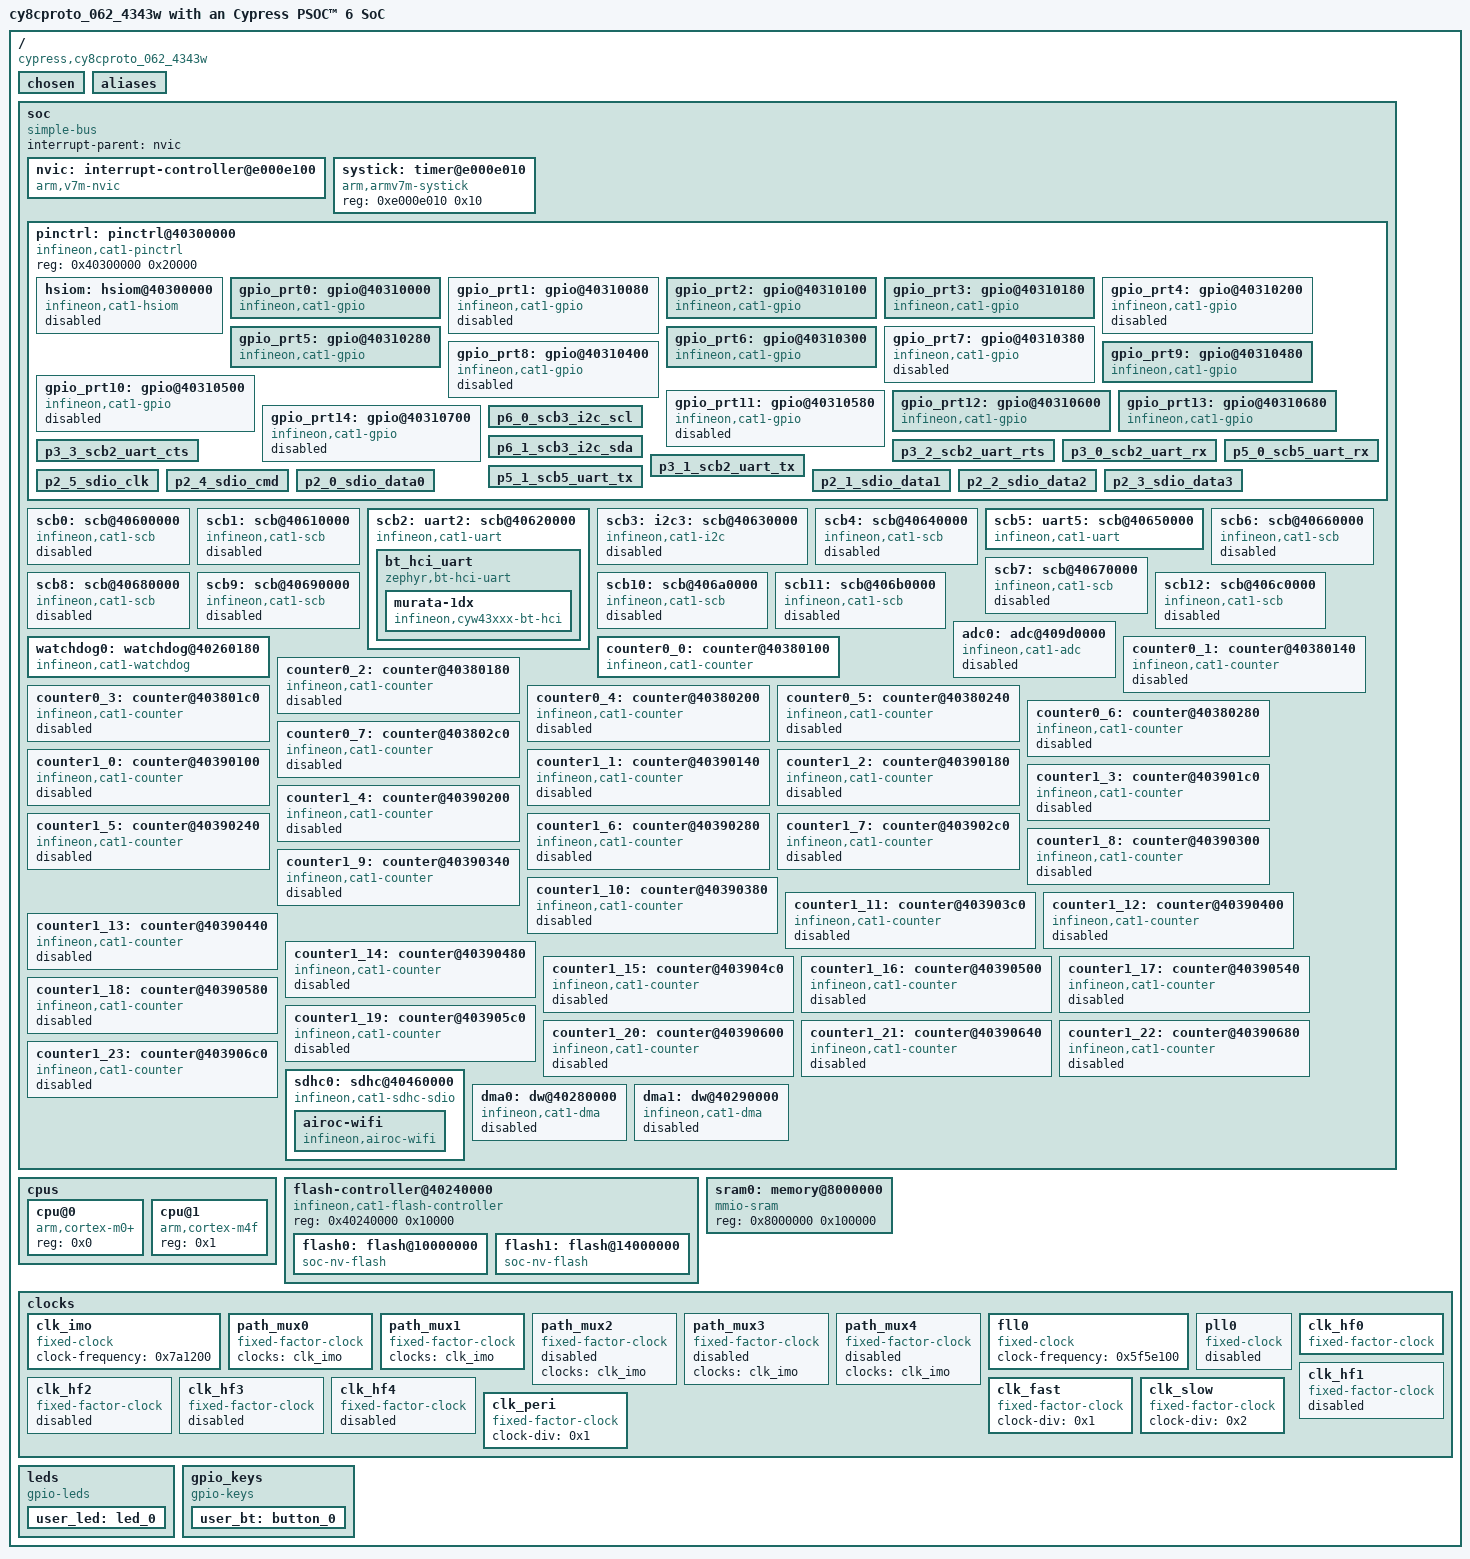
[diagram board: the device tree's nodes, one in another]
/dts-v1/;

/* node '/' defined in zephyr/dts/common/skeleton.dtsi:9 */
/ {
	#address-cells = < 0x1 >;                                  /* in zephyr/dts/common/skeleton.dtsi:10 */
	#size-cells = < 0x1 >;                                     /* in zephyr/dts/common/skeleton.dtsi:11 */
	model = "cy8cproto_062_4343w with an Cypress PSOC™ 6 SoC"; /* in zephyr/boards/infineon/cy8cproto_062_4343w/cy8cproto_062_4343w.dts:13 */
	compatible = "cypress,cy8cproto_062_4343w",
	             "cypress,PSOC6";                              /* in zephyr/boards/infineon/cy8cproto_062_4343w/cy8cproto_062_4343w.dts:14 */

	/* node '/chosen' defined in zephyr/dts/common/skeleton.dtsi:13 */
	chosen {
		zephyr,sram = &sram0;         /* in zephyr/boards/infineon/cy8cproto_062_4343w/cy8cproto_062_4343w.dts:24 */
		zephyr,flash = &flash0;       /* in zephyr/boards/infineon/cy8cproto_062_4343w/cy8cproto_062_4343w.dts:25 */
		zephyr,console = &uart5;      /* in zephyr/boards/infineon/cy8cproto_062_4343w/cy8cproto_062_4343w.dts:26 */
		zephyr,shell-uart = &uart5;   /* in zephyr/boards/infineon/cy8cproto_062_4343w/cy8cproto_062_4343w.dts:27 */
		zephyr,bt-hci = &bt_hci_uart; /* in zephyr/boards/infineon/cy8cproto_062_4343w/cy8cproto_062_4343w.dts:28 */
	};

	/* node '/aliases' defined in zephyr/dts/common/skeleton.dtsi:15 */
	aliases {
		led0 = &user_led;       /* in zephyr/boards/infineon/cy8cproto_062_4343w/cy8cproto_062_4343w-common.dtsi:10 */
		sw0 = &user_bt;         /* in zephyr/boards/infineon/cy8cproto_062_4343w/cy8cproto_062_4343w-common.dtsi:11 */
		uart-5 = &uart5;        /* in zephyr/boards/infineon/cy8cproto_062_4343w/cy8cproto_062_4343w.dts:17 */
		i2c-0 = &i2c3;          /* in zephyr/boards/infineon/cy8cproto_062_4343w/cy8cproto_062_4343w.dts:18 */
		watchdog0 = &watchdog0; /* in zephyr/boards/infineon/cy8cproto_062_4343w/cy8cproto_062_4343w.dts:19 */
		sdhc0 = &sdhc0;         /* in zephyr/boards/infineon/cy8cproto_062_4343w/cy8cproto_062_4343w.dts:20 */
	};

	/* node '/soc' defined in zephyr/dts/arm/armv7-m.dtsi:6 */
	soc {
		#address-cells = < 0x1 >;     /* in zephyr/dts/arm/armv7-m.dtsi:7 */
		#size-cells = < 0x1 >;        /* in zephyr/dts/arm/armv7-m.dtsi:8 */
		compatible = "simple-bus";    /* in zephyr/dts/arm/armv7-m.dtsi:9 */
		interrupt-parent = < &nvic >; /* in zephyr/dts/arm/armv7-m.dtsi:10 */
		ranges;                       /* in zephyr/dts/arm/armv7-m.dtsi:11 */

		/* node '/soc/interrupt-controller@e000e100' defined in zephyr/dts/arm/armv7-m.dtsi:13 */
		nvic: interrupt-controller@e000e100 {
			#address-cells = < 0x1 >;            /* in zephyr/dts/arm/armv7-m.dtsi:14 */
			compatible = "arm,v7m-nvic";         /* in zephyr/dts/arm/armv7-m.dtsi:15 */
			reg = < 0xe000e100 0xc00 >;          /* in zephyr/dts/arm/armv7-m.dtsi:16 */
			interrupt-controller;                /* in zephyr/dts/arm/armv7-m.dtsi:17 */
			#interrupt-cells = < 0x2 >;          /* in zephyr/dts/arm/armv7-m.dtsi:18 */
			arm,num-irq-priority-bits = < 0x3 >; /* in zephyr/dts/arm/infineon/cat1a/mpns/CY8C624ABZI_S2D44.dtsi:12 */
			phandle = < 0x1 >;                   /* in zephyr/dts/arm/armv7-m.dtsi:10 */
		};

		/* node '/soc/timer@e000e010' defined in zephyr/dts/arm/armv7-m.dtsi:21 */
		systick: timer@e000e010 {
			compatible = "arm,armv7m-systick"; /* in zephyr/dts/arm/armv7-m.dtsi:22 */
			reg = < 0xe000e010 0x10 >;         /* in zephyr/dts/arm/armv7-m.dtsi:23 */
		};

		/* node '/soc/pinctrl@40300000' defined in zephyr/dts/arm/infineon/cat1a/psoc6_02/psoc6_02.dtsi:55 */
		pinctrl: pinctrl@40300000 {
			compatible = "infineon,cat1-pinctrl"; /* in zephyr/dts/arm/infineon/cat1a/psoc6_02/psoc6_02.dtsi:56 */
			reg = < 0x40300000 0x20000 >;         /* in zephyr/dts/arm/infineon/cat1a/psoc6_02/psoc6_02.dtsi:57 */
			#address-cells = < 0x1 >;             /* in zephyr/dts/arm/infineon/cat1a/psoc6_02/psoc6_02.dtsi:58 */
			#size-cells = < 0x0 >;                /* in zephyr/dts/arm/infineon/cat1a/psoc6_02/psoc6_02.dtsi:59 */

			/* node '/soc/pinctrl@40300000/hsiom@40300000' defined in zephyr/dts/arm/infineon/cat1a/psoc6_02/psoc6_02.dtsi:61 */
			hsiom: hsiom@40300000 {
				compatible = "infineon,cat1-hsiom"; /* in zephyr/dts/arm/infineon/cat1a/psoc6_02/psoc6_02.dtsi:62 */
				reg = < 0x40300000 0x4000 >;        /* in zephyr/dts/arm/infineon/cat1a/psoc6_02/psoc6_02.dtsi:63 */
				interrupts = < 0xf 0x6 >,
				             < 0x10 0x6 >;          /* in zephyr/dts/arm/infineon/cat1a/psoc6_02/psoc6_02.dtsi:64 */
				status = "disabled";                /* in zephyr/dts/arm/infineon/cat1a/psoc6_02/psoc6_02.dtsi:65 */
			};

			/* node '/soc/pinctrl@40300000/gpio@40310000' defined in zephyr/dts/arm/infineon/cat1a/psoc6_02/psoc6_02.dtsi:68 */
			gpio_prt0: gpio@40310000 {
				compatible = "infineon,cat1-gpio"; /* in zephyr/dts/arm/infineon/cat1a/psoc6_02/psoc6_02.dtsi:69 */
				reg = < 0x40310000 0x80 >;         /* in zephyr/dts/arm/infineon/cat1a/psoc6_02/psoc6_02.dtsi:70 */
				interrupts = < 0x0 0x6 >;          /* in zephyr/dts/arm/infineon/cat1a/psoc6_02/psoc6_02.dtsi:71 */
				gpio-controller;                   /* in zephyr/dts/arm/infineon/cat1a/psoc6_02/psoc6_02.dtsi:72 */
				ngpios = < 0x6 >;                  /* in zephyr/dts/arm/infineon/cat1a/psoc6_02/psoc6_02.dtsi:73 */
				#gpio-cells = < 0x2 >;             /* in zephyr/dts/arm/infineon/cat1a/psoc6_02/psoc6_02.dtsi:75 */
				status = "okay";                   /* in zephyr/boards/infineon/cy8cproto_062_4343w/cy8cproto_062_4343w-common.dtsi:35 */
				phandle = < 0x12 >;                /* in zephyr/boards/infineon/cy8cproto_062_4343w/cy8cproto_062_4343w.dts:95 */
			};

			/* node '/soc/pinctrl@40300000/gpio@40310080' defined in zephyr/dts/arm/infineon/cat1a/psoc6_02/psoc6_02.dtsi:78 */
			gpio_prt1: gpio@40310080 {
				compatible = "infineon,cat1-gpio"; /* in zephyr/dts/arm/infineon/cat1a/psoc6_02/psoc6_02.dtsi:79 */
				reg = < 0x40310080 0x80 >;         /* in zephyr/dts/arm/infineon/cat1a/psoc6_02/psoc6_02.dtsi:80 */
				interrupts = < 0x1 0x6 >;          /* in zephyr/dts/arm/infineon/cat1a/psoc6_02/psoc6_02.dtsi:81 */
				gpio-controller;                   /* in zephyr/dts/arm/infineon/cat1a/psoc6_02/psoc6_02.dtsi:82 */
				ngpios = < 0x6 >;                  /* in zephyr/dts/arm/infineon/cat1a/psoc6_02/psoc6_02.dtsi:83 */
				status = "disabled";               /* in zephyr/dts/arm/infineon/cat1a/psoc6_02/psoc6_02.dtsi:84 */
				#gpio-cells = < 0x2 >;             /* in zephyr/dts/arm/infineon/cat1a/psoc6_02/psoc6_02.dtsi:85 */
			};

			/* node '/soc/pinctrl@40300000/gpio@40310100' defined in zephyr/dts/arm/infineon/cat1a/psoc6_02/psoc6_02.dtsi:88 */
			gpio_prt2: gpio@40310100 {
				compatible = "infineon,cat1-gpio"; /* in zephyr/dts/arm/infineon/cat1a/psoc6_02/psoc6_02.dtsi:89 */
				reg = < 0x40310100 0x80 >;         /* in zephyr/dts/arm/infineon/cat1a/psoc6_02/psoc6_02.dtsi:90 */
				interrupts = < 0x2 0x6 >;          /* in zephyr/dts/arm/infineon/cat1a/psoc6_02/psoc6_02.dtsi:91 */
				gpio-controller;                   /* in zephyr/dts/arm/infineon/cat1a/psoc6_02/psoc6_02.dtsi:92 */
				ngpios = < 0x8 >;                  /* in zephyr/dts/arm/infineon/cat1a/psoc6_02/psoc6_02.dtsi:93 */
				#gpio-cells = < 0x2 >;             /* in zephyr/dts/arm/infineon/cat1a/psoc6_02/psoc6_02.dtsi:95 */
				status = "okay";                   /* in zephyr/boards/infineon/cy8cproto_062_4343w/cy8cproto_062_4343w-common.dtsi:39 */
				phandle = < 0x11 >;                /* in zephyr/boards/infineon/cy8cproto_062_4343w/cy8cproto_062_4343w.dts:94 */
			};

			/* node '/soc/pinctrl@40300000/gpio@40310180' defined in zephyr/dts/arm/infineon/cat1a/psoc6_02/psoc6_02.dtsi:98 */
			gpio_prt3: gpio@40310180 {
				compatible = "infineon,cat1-gpio"; /* in zephyr/dts/arm/infineon/cat1a/psoc6_02/psoc6_02.dtsi:99 */
				reg = < 0x40310180 0x80 >;         /* in zephyr/dts/arm/infineon/cat1a/psoc6_02/psoc6_02.dtsi:100 */
				interrupts = < 0x3 0x6 >;          /* in zephyr/dts/arm/infineon/cat1a/psoc6_02/psoc6_02.dtsi:101 */
				gpio-controller;                   /* in zephyr/dts/arm/infineon/cat1a/psoc6_02/psoc6_02.dtsi:102 */
				ngpios = < 0x6 >;                  /* in zephyr/dts/arm/infineon/cat1a/psoc6_02/psoc6_02.dtsi:103 */
				#gpio-cells = < 0x2 >;             /* in zephyr/dts/arm/infineon/cat1a/psoc6_02/psoc6_02.dtsi:105 */
				status = "okay";                   /* in zephyr/boards/infineon/cy8cproto_062_4343w/cy8cproto_062_4343w-common.dtsi:43 */
				phandle = < 0x6 >;                 /* in zephyr/boards/infineon/cy8cproto_062_4343w/cy8cproto_062_4343w.dts:67 */
			};

			/* node '/soc/pinctrl@40300000/gpio@40310200' defined in zephyr/dts/arm/infineon/cat1a/psoc6_02/psoc6_02.dtsi:108 */
			gpio_prt4: gpio@40310200 {
				compatible = "infineon,cat1-gpio"; /* in zephyr/dts/arm/infineon/cat1a/psoc6_02/psoc6_02.dtsi:109 */
				reg = < 0x40310200 0x80 >;         /* in zephyr/dts/arm/infineon/cat1a/psoc6_02/psoc6_02.dtsi:110 */
				interrupts = < 0x4 0x6 >;          /* in zephyr/dts/arm/infineon/cat1a/psoc6_02/psoc6_02.dtsi:111 */
				gpio-controller;                   /* in zephyr/dts/arm/infineon/cat1a/psoc6_02/psoc6_02.dtsi:112 */
				ngpios = < 0x2 >;                  /* in zephyr/dts/arm/infineon/cat1a/psoc6_02/psoc6_02.dtsi:113 */
				status = "disabled";               /* in zephyr/dts/arm/infineon/cat1a/psoc6_02/psoc6_02.dtsi:114 */
				#gpio-cells = < 0x2 >;             /* in zephyr/dts/arm/infineon/cat1a/psoc6_02/psoc6_02.dtsi:115 */
			};

			/* node '/soc/pinctrl@40300000/gpio@40310280' defined in zephyr/dts/arm/infineon/cat1a/psoc6_02/psoc6_02.dtsi:118 */
			gpio_prt5: gpio@40310280 {
				compatible = "infineon,cat1-gpio"; /* in zephyr/dts/arm/infineon/cat1a/psoc6_02/psoc6_02.dtsi:119 */
				reg = < 0x40310280 0x80 >;         /* in zephyr/dts/arm/infineon/cat1a/psoc6_02/psoc6_02.dtsi:120 */
				interrupts = < 0x5 0x6 >;          /* in zephyr/dts/arm/infineon/cat1a/psoc6_02/psoc6_02.dtsi:121 */
				gpio-controller;                   /* in zephyr/dts/arm/infineon/cat1a/psoc6_02/psoc6_02.dtsi:122 */
				ngpios = < 0x8 >;                  /* in zephyr/dts/arm/infineon/cat1a/psoc6_02/psoc6_02.dtsi:123 */
				#gpio-cells = < 0x2 >;             /* in zephyr/dts/arm/infineon/cat1a/psoc6_02/psoc6_02.dtsi:125 */
				status = "okay";                   /* in zephyr/boards/infineon/cy8cproto_062_4343w/cy8cproto_062_4343w-common.dtsi:47 */
			};

			/* node '/soc/pinctrl@40300000/gpio@40310300' defined in zephyr/dts/arm/infineon/cat1a/psoc6_02/psoc6_02.dtsi:128 */
			gpio_prt6: gpio@40310300 {
				compatible = "infineon,cat1-gpio"; /* in zephyr/dts/arm/infineon/cat1a/psoc6_02/psoc6_02.dtsi:129 */
				reg = < 0x40310300 0x80 >;         /* in zephyr/dts/arm/infineon/cat1a/psoc6_02/psoc6_02.dtsi:130 */
				interrupts = < 0x6 0x6 >;          /* in zephyr/dts/arm/infineon/cat1a/psoc6_02/psoc6_02.dtsi:131 */
				gpio-controller;                   /* in zephyr/dts/arm/infineon/cat1a/psoc6_02/psoc6_02.dtsi:132 */
				ngpios = < 0x8 >;                  /* in zephyr/dts/arm/infineon/cat1a/psoc6_02/psoc6_02.dtsi:133 */
				#gpio-cells = < 0x2 >;             /* in zephyr/dts/arm/infineon/cat1a/psoc6_02/psoc6_02.dtsi:135 */
				status = "okay";                   /* in zephyr/boards/infineon/cy8cproto_062_4343w/cy8cproto_062_4343w-common.dtsi:51 */
			};

			/* node '/soc/pinctrl@40300000/gpio@40310380' defined in zephyr/dts/arm/infineon/cat1a/psoc6_02/psoc6_02.dtsi:138 */
			gpio_prt7: gpio@40310380 {
				compatible = "infineon,cat1-gpio"; /* in zephyr/dts/arm/infineon/cat1a/psoc6_02/psoc6_02.dtsi:139 */
				reg = < 0x40310380 0x80 >;         /* in zephyr/dts/arm/infineon/cat1a/psoc6_02/psoc6_02.dtsi:140 */
				interrupts = < 0x7 0x6 >;          /* in zephyr/dts/arm/infineon/cat1a/psoc6_02/psoc6_02.dtsi:141 */
				gpio-controller;                   /* in zephyr/dts/arm/infineon/cat1a/psoc6_02/psoc6_02.dtsi:142 */
				ngpios = < 0x8 >;                  /* in zephyr/dts/arm/infineon/cat1a/psoc6_02/psoc6_02.dtsi:143 */
				status = "disabled";               /* in zephyr/dts/arm/infineon/cat1a/psoc6_02/psoc6_02.dtsi:144 */
				#gpio-cells = < 0x2 >;             /* in zephyr/dts/arm/infineon/cat1a/psoc6_02/psoc6_02.dtsi:145 */
			};

			/* node '/soc/pinctrl@40300000/gpio@40310400' defined in zephyr/dts/arm/infineon/cat1a/psoc6_02/psoc6_02.dtsi:148 */
			gpio_prt8: gpio@40310400 {
				compatible = "infineon,cat1-gpio"; /* in zephyr/dts/arm/infineon/cat1a/psoc6_02/psoc6_02.dtsi:149 */
				reg = < 0x40310400 0x80 >;         /* in zephyr/dts/arm/infineon/cat1a/psoc6_02/psoc6_02.dtsi:150 */
				interrupts = < 0x8 0x6 >;          /* in zephyr/dts/arm/infineon/cat1a/psoc6_02/psoc6_02.dtsi:151 */
				gpio-controller;                   /* in zephyr/dts/arm/infineon/cat1a/psoc6_02/psoc6_02.dtsi:152 */
				ngpios = < 0x8 >;                  /* in zephyr/dts/arm/infineon/cat1a/psoc6_02/psoc6_02.dtsi:153 */
				status = "disabled";               /* in zephyr/dts/arm/infineon/cat1a/psoc6_02/psoc6_02.dtsi:154 */
				#gpio-cells = < 0x2 >;             /* in zephyr/dts/arm/infineon/cat1a/psoc6_02/psoc6_02.dtsi:155 */
			};

			/* node '/soc/pinctrl@40300000/gpio@40310480' defined in zephyr/dts/arm/infineon/cat1a/psoc6_02/psoc6_02.dtsi:158 */
			gpio_prt9: gpio@40310480 {
				compatible = "infineon,cat1-gpio"; /* in zephyr/dts/arm/infineon/cat1a/psoc6_02/psoc6_02.dtsi:159 */
				reg = < 0x40310480 0x80 >;         /* in zephyr/dts/arm/infineon/cat1a/psoc6_02/psoc6_02.dtsi:160 */
				interrupts = < 0x9 0x6 >;          /* in zephyr/dts/arm/infineon/cat1a/psoc6_02/psoc6_02.dtsi:161 */
				gpio-controller;                   /* in zephyr/dts/arm/infineon/cat1a/psoc6_02/psoc6_02.dtsi:162 */
				ngpios = < 0x8 >;                  /* in zephyr/dts/arm/infineon/cat1a/psoc6_02/psoc6_02.dtsi:163 */
				#gpio-cells = < 0x2 >;             /* in zephyr/dts/arm/infineon/cat1a/psoc6_02/psoc6_02.dtsi:165 */
				status = "okay";                   /* in zephyr/boards/infineon/cy8cproto_062_4343w/cy8cproto_062_4343w-common.dtsi:55 */
			};

			/* node '/soc/pinctrl@40300000/gpio@40310500' defined in zephyr/dts/arm/infineon/cat1a/psoc6_02/psoc6_02.dtsi:168 */
			gpio_prt10: gpio@40310500 {
				compatible = "infineon,cat1-gpio"; /* in zephyr/dts/arm/infineon/cat1a/psoc6_02/psoc6_02.dtsi:169 */
				reg = < 0x40310500 0x80 >;         /* in zephyr/dts/arm/infineon/cat1a/psoc6_02/psoc6_02.dtsi:170 */
				interrupts = < 0xa 0x6 >;          /* in zephyr/dts/arm/infineon/cat1a/psoc6_02/psoc6_02.dtsi:171 */
				gpio-controller;                   /* in zephyr/dts/arm/infineon/cat1a/psoc6_02/psoc6_02.dtsi:172 */
				ngpios = < 0x8 >;                  /* in zephyr/dts/arm/infineon/cat1a/psoc6_02/psoc6_02.dtsi:173 */
				status = "disabled";               /* in zephyr/dts/arm/infineon/cat1a/psoc6_02/psoc6_02.dtsi:174 */
				#gpio-cells = < 0x2 >;             /* in zephyr/dts/arm/infineon/cat1a/psoc6_02/psoc6_02.dtsi:175 */
			};

			/* node '/soc/pinctrl@40300000/gpio@40310580' defined in zephyr/dts/arm/infineon/cat1a/psoc6_02/psoc6_02.dtsi:178 */
			gpio_prt11: gpio@40310580 {
				compatible = "infineon,cat1-gpio"; /* in zephyr/dts/arm/infineon/cat1a/psoc6_02/psoc6_02.dtsi:179 */
				reg = < 0x40310580 0x80 >;         /* in zephyr/dts/arm/infineon/cat1a/psoc6_02/psoc6_02.dtsi:180 */
				interrupts = < 0xb 0x6 >;          /* in zephyr/dts/arm/infineon/cat1a/psoc6_02/psoc6_02.dtsi:181 */
				gpio-controller;                   /* in zephyr/dts/arm/infineon/cat1a/psoc6_02/psoc6_02.dtsi:182 */
				ngpios = < 0x8 >;                  /* in zephyr/dts/arm/infineon/cat1a/psoc6_02/psoc6_02.dtsi:183 */
				status = "disabled";               /* in zephyr/dts/arm/infineon/cat1a/psoc6_02/psoc6_02.dtsi:184 */
				#gpio-cells = < 0x2 >;             /* in zephyr/dts/arm/infineon/cat1a/psoc6_02/psoc6_02.dtsi:185 */
			};

			/* node '/soc/pinctrl@40300000/gpio@40310600' defined in zephyr/dts/arm/infineon/cat1a/psoc6_02/psoc6_02.dtsi:188 */
			gpio_prt12: gpio@40310600 {
				compatible = "infineon,cat1-gpio"; /* in zephyr/dts/arm/infineon/cat1a/psoc6_02/psoc6_02.dtsi:189 */
				reg = < 0x40310600 0x80 >;         /* in zephyr/dts/arm/infineon/cat1a/psoc6_02/psoc6_02.dtsi:190 */
				interrupts = < 0xc 0x6 >;          /* in zephyr/dts/arm/infineon/cat1a/psoc6_02/psoc6_02.dtsi:191 */
				gpio-controller;                   /* in zephyr/dts/arm/infineon/cat1a/psoc6_02/psoc6_02.dtsi:192 */
				ngpios = < 0x8 >;                  /* in zephyr/dts/arm/infineon/cat1a/psoc6_02/psoc6_02.dtsi:193 */
				#gpio-cells = < 0x2 >;             /* in zephyr/dts/arm/infineon/cat1a/psoc6_02/psoc6_02.dtsi:195 */
				status = "okay";                   /* in zephyr/boards/infineon/cy8cproto_062_4343w/cy8cproto_062_4343w-common.dtsi:59 */
			};

			/* node '/soc/pinctrl@40300000/gpio@40310680' defined in zephyr/dts/arm/infineon/cat1a/psoc6_02/psoc6_02.dtsi:198 */
			gpio_prt13: gpio@40310680 {
				compatible = "infineon,cat1-gpio"; /* in zephyr/dts/arm/infineon/cat1a/psoc6_02/psoc6_02.dtsi:199 */
				reg = < 0x40310680 0x80 >;         /* in zephyr/dts/arm/infineon/cat1a/psoc6_02/psoc6_02.dtsi:200 */
				interrupts = < 0xd 0x6 >;          /* in zephyr/dts/arm/infineon/cat1a/psoc6_02/psoc6_02.dtsi:201 */
				gpio-controller;                   /* in zephyr/dts/arm/infineon/cat1a/psoc6_02/psoc6_02.dtsi:202 */
				ngpios = < 0x8 >;                  /* in zephyr/dts/arm/infineon/cat1a/psoc6_02/psoc6_02.dtsi:203 */
				#gpio-cells = < 0x2 >;             /* in zephyr/dts/arm/infineon/cat1a/psoc6_02/psoc6_02.dtsi:205 */
				status = "okay";                   /* in zephyr/boards/infineon/cy8cproto_062_4343w/cy8cproto_062_4343w-common.dtsi:63 */
				phandle = < 0x19 >;                /* in zephyr/boards/infineon/cy8cproto_062_4343w/cy8cproto_062_4343w-common.dtsi:19 */
			};

			/* node '/soc/pinctrl@40300000/gpio@40310700' defined in zephyr/dts/arm/infineon/cat1a/psoc6_02/psoc6_02.dtsi:208 */
			gpio_prt14: gpio@40310700 {
				compatible = "infineon,cat1-gpio"; /* in zephyr/dts/arm/infineon/cat1a/psoc6_02/psoc6_02.dtsi:209 */
				reg = < 0x40310700 0x80 >;         /* in zephyr/dts/arm/infineon/cat1a/psoc6_02/psoc6_02.dtsi:210 */
				interrupts = < 0xe 0x6 >;          /* in zephyr/dts/arm/infineon/cat1a/psoc6_02/psoc6_02.dtsi:211 */
				gpio-controller;                   /* in zephyr/dts/arm/infineon/cat1a/psoc6_02/psoc6_02.dtsi:212 */
				ngpios = < 0x2 >;                  /* in zephyr/dts/arm/infineon/cat1a/psoc6_02/psoc6_02.dtsi:213 */
				status = "disabled";               /* in zephyr/dts/arm/infineon/cat1a/psoc6_02/psoc6_02.dtsi:214 */
				#gpio-cells = < 0x2 >;             /* in zephyr/dts/arm/infineon/cat1a/psoc6_02/psoc6_02.dtsi:215 */
			};

			/* node '/soc/pinctrl@40300000/p6_0_scb3_i2c_scl' defined in zephyr/dts/arm/infineon/cat1a/psoc6_02/psoc6_02.124-bga.dtsi:48 */
			p6_0_scb3_i2c_scl: p6_0_scb3_i2c_scl {
				pinmux = < 0x130006 >; /* in zephyr/dts/arm/infineon/cat1a/psoc6_02/psoc6_02.124-bga.dtsi:49 */
				drive-open-drain;      /* in zephyr/boards/infineon/cy8cproto_062_4343w/cy8cproto_062_4343w-pinctrl.dtsi:34 */
				input-enable;          /* in zephyr/boards/infineon/cy8cproto_062_4343w/cy8cproto_062_4343w-pinctrl.dtsi:35 */
				phandle = < 0x7 >;     /* in zephyr/boards/infineon/cy8cproto_062_4343w/cy8cproto_062_4343w.dts:135 */
			};

			/* node '/soc/pinctrl@40300000/p6_1_scb3_i2c_sda' defined in zephyr/dts/arm/infineon/cat1a/psoc6_02/psoc6_02.124-bga.dtsi:133 */
			p6_1_scb3_i2c_sda: p6_1_scb3_i2c_sda {
				pinmux = < 0x130106 >; /* in zephyr/dts/arm/infineon/cat1a/psoc6_02/psoc6_02.124-bga.dtsi:134 */
				drive-open-drain;      /* in zephyr/boards/infineon/cy8cproto_062_4343w/cy8cproto_062_4343w-pinctrl.dtsi:39 */
				input-enable;          /* in zephyr/boards/infineon/cy8cproto_062_4343w/cy8cproto_062_4343w-pinctrl.dtsi:40 */
				phandle = < 0x8 >;     /* in zephyr/boards/infineon/cy8cproto_062_4343w/cy8cproto_062_4343w.dts:135 */
			};

			/* node '/soc/pinctrl@40300000/p3_3_scb2_uart_cts' defined in zephyr/dts/arm/infineon/cat1a/psoc6_02/psoc6_02.124-bga.dtsi:202 */
			p3_3_scb2_uart_cts: p3_3_scb2_uart_cts {
				pinmux = < 0x120303 >; /* in zephyr/dts/arm/infineon/cat1a/psoc6_02/psoc6_02.124-bga.dtsi:203 */
				input-enable;          /* in zephyr/boards/infineon/cy8cproto_062_4343w/cy8cproto_062_4343w-pinctrl.dtsi:20 */
				phandle = < 0x5 >;     /* in zephyr/boards/infineon/cy8cproto_062_4343w/cy8cproto_062_4343w.dts:55 */
			};

			/* node '/soc/pinctrl@40300000/p3_2_scb2_uart_rts' defined in zephyr/dts/arm/infineon/cat1a/psoc6_02/psoc6_02.124-bga.dtsi:275 */
			p3_2_scb2_uart_rts: p3_2_scb2_uart_rts {
				pinmux = < 0x120203 >; /* in zephyr/dts/arm/infineon/cat1a/psoc6_02/psoc6_02.124-bga.dtsi:276 */
				drive-push-pull;       /* in zephyr/boards/infineon/cy8cproto_062_4343w/cy8cproto_062_4343w-pinctrl.dtsi:16 */
				phandle = < 0x4 >;     /* in zephyr/boards/infineon/cy8cproto_062_4343w/cy8cproto_062_4343w.dts:55 */
			};

			/* node '/soc/pinctrl@40300000/p3_0_scb2_uart_rx' defined in zephyr/dts/arm/infineon/cat1a/psoc6_02/psoc6_02.124-bga.dtsi:348 */
			p3_0_scb2_uart_rx: p3_0_scb2_uart_rx {
				pinmux = < 0x120003 >; /* in zephyr/dts/arm/infineon/cat1a/psoc6_02/psoc6_02.124-bga.dtsi:349 */
				input-enable;          /* in zephyr/boards/infineon/cy8cproto_062_4343w/cy8cproto_062_4343w-pinctrl.dtsi:12 */
				phandle = < 0x3 >;     /* in zephyr/boards/infineon/cy8cproto_062_4343w/cy8cproto_062_4343w.dts:55 */
			};

			/* node '/soc/pinctrl@40300000/p5_0_scb5_uart_rx' defined in zephyr/dts/arm/infineon/cat1a/psoc6_02/psoc6_02.124-bga.dtsi:356 */
			p5_0_scb5_uart_rx: p5_0_scb5_uart_rx {
				pinmux = < 0x120005 >; /* in zephyr/dts/arm/infineon/cat1a/psoc6_02/psoc6_02.124-bga.dtsi:357 */
				input-enable;          /* in zephyr/boards/infineon/cy8cproto_062_4343w/cy8cproto_062_4343w-pinctrl.dtsi:29 */
				phandle = < 0xa >;     /* in zephyr/boards/infineon/cy8cproto_062_4343w/cy8cproto_062_4343w.dts:41 */
			};

			/* node '/soc/pinctrl@40300000/p3_1_scb2_uart_tx' defined in zephyr/dts/arm/infineon/cat1a/psoc6_02/psoc6_02.124-bga.dtsi:425 */
			p3_1_scb2_uart_tx: p3_1_scb2_uart_tx {
				pinmux = < 0x120103 >; /* in zephyr/dts/arm/infineon/cat1a/psoc6_02/psoc6_02.124-bga.dtsi:426 */
				drive-push-pull;       /* in zephyr/boards/infineon/cy8cproto_062_4343w/cy8cproto_062_4343w-pinctrl.dtsi:8 */
				phandle = < 0x2 >;     /* in zephyr/boards/infineon/cy8cproto_062_4343w/cy8cproto_062_4343w.dts:55 */
			};

			/* node '/soc/pinctrl@40300000/p5_1_scb5_uart_tx' defined in zephyr/dts/arm/infineon/cat1a/psoc6_02/psoc6_02.124-bga.dtsi:433 */
			p5_1_scb5_uart_tx: p5_1_scb5_uart_tx {
				pinmux = < 0x120105 >; /* in zephyr/dts/arm/infineon/cat1a/psoc6_02/psoc6_02.124-bga.dtsi:434 */
				drive-push-pull;       /* in zephyr/boards/infineon/cy8cproto_062_4343w/cy8cproto_062_4343w-pinctrl.dtsi:25 */
				phandle = < 0x9 >;     /* in zephyr/boards/infineon/cy8cproto_062_4343w/cy8cproto_062_4343w.dts:41 */
			};

			/* node '/soc/pinctrl@40300000/p2_5_sdio_clk' defined in zephyr/boards/infineon/cy8cproto_062_4343w/cy8cproto_062_4343w-pinctrl.dtsi:45 */
			p2_5_sdio_clk: p2_5_sdio_clk {
				pinmux = < 0x1a0502 >; /* in zephyr/boards/infineon/cy8cproto_062_4343w/cy8cproto_062_4343w-pinctrl.dtsi:46 */
				drive-push-pull;       /* in zephyr/boards/infineon/cy8cproto_062_4343w/cy8cproto_062_4343w-pinctrl.dtsi:47 */
				input-enable;          /* in zephyr/boards/infineon/cy8cproto_062_4343w/cy8cproto_062_4343w-pinctrl.dtsi:48 */
				phandle = < 0xc >;     /* in zephyr/boards/infineon/cy8cproto_062_4343w/cy8cproto_062_4343w.dts:84 */
			};

			/* node '/soc/pinctrl@40300000/p2_4_sdio_cmd' defined in zephyr/boards/infineon/cy8cproto_062_4343w/cy8cproto_062_4343w-pinctrl.dtsi:51 */
			p2_4_sdio_cmd: p2_4_sdio_cmd {
				pinmux = < 0x1a0402 >; /* in zephyr/boards/infineon/cy8cproto_062_4343w/cy8cproto_062_4343w-pinctrl.dtsi:52 */
				drive-push-pull;       /* in zephyr/boards/infineon/cy8cproto_062_4343w/cy8cproto_062_4343w-pinctrl.dtsi:53 */
				input-enable;          /* in zephyr/boards/infineon/cy8cproto_062_4343w/cy8cproto_062_4343w-pinctrl.dtsi:54 */
				phandle = < 0xb >;     /* in zephyr/boards/infineon/cy8cproto_062_4343w/cy8cproto_062_4343w.dts:84 */
			};

			/* node '/soc/pinctrl@40300000/p2_0_sdio_data0' defined in zephyr/boards/infineon/cy8cproto_062_4343w/cy8cproto_062_4343w-pinctrl.dtsi:57 */
			p2_0_sdio_data0: p2_0_sdio_data0 {
				pinmux = < 0x1a0002 >; /* in zephyr/boards/infineon/cy8cproto_062_4343w/cy8cproto_062_4343w-pinctrl.dtsi:58 */
				drive-push-pull;       /* in zephyr/boards/infineon/cy8cproto_062_4343w/cy8cproto_062_4343w-pinctrl.dtsi:59 */
				input-enable;          /* in zephyr/boards/infineon/cy8cproto_062_4343w/cy8cproto_062_4343w-pinctrl.dtsi:60 */
				phandle = < 0xd >;     /* in zephyr/boards/infineon/cy8cproto_062_4343w/cy8cproto_062_4343w.dts:84 */
			};

			/* node '/soc/pinctrl@40300000/p2_1_sdio_data1' defined in zephyr/boards/infineon/cy8cproto_062_4343w/cy8cproto_062_4343w-pinctrl.dtsi:63 */
			p2_1_sdio_data1: p2_1_sdio_data1 {
				pinmux = < 0x1a0102 >; /* in zephyr/boards/infineon/cy8cproto_062_4343w/cy8cproto_062_4343w-pinctrl.dtsi:64 */
				drive-push-pull;       /* in zephyr/boards/infineon/cy8cproto_062_4343w/cy8cproto_062_4343w-pinctrl.dtsi:65 */
				input-enable;          /* in zephyr/boards/infineon/cy8cproto_062_4343w/cy8cproto_062_4343w-pinctrl.dtsi:66 */
				phandle = < 0xe >;     /* in zephyr/boards/infineon/cy8cproto_062_4343w/cy8cproto_062_4343w.dts:84 */
			};

			/* node '/soc/pinctrl@40300000/p2_2_sdio_data2' defined in zephyr/boards/infineon/cy8cproto_062_4343w/cy8cproto_062_4343w-pinctrl.dtsi:69 */
			p2_2_sdio_data2: p2_2_sdio_data2 {
				pinmux = < 0x1a0202 >; /* in zephyr/boards/infineon/cy8cproto_062_4343w/cy8cproto_062_4343w-pinctrl.dtsi:70 */
				drive-push-pull;       /* in zephyr/boards/infineon/cy8cproto_062_4343w/cy8cproto_062_4343w-pinctrl.dtsi:71 */
				input-enable;          /* in zephyr/boards/infineon/cy8cproto_062_4343w/cy8cproto_062_4343w-pinctrl.dtsi:72 */
				phandle = < 0xf >;     /* in zephyr/boards/infineon/cy8cproto_062_4343w/cy8cproto_062_4343w.dts:84 */
			};

			/* node '/soc/pinctrl@40300000/p2_3_sdio_data3' defined in zephyr/boards/infineon/cy8cproto_062_4343w/cy8cproto_062_4343w-pinctrl.dtsi:75 */
			p2_3_sdio_data3: p2_3_sdio_data3 {
				pinmux = < 0x1a0302 >; /* in zephyr/boards/infineon/cy8cproto_062_4343w/cy8cproto_062_4343w-pinctrl.dtsi:76 */
				drive-push-pull;       /* in zephyr/boards/infineon/cy8cproto_062_4343w/cy8cproto_062_4343w-pinctrl.dtsi:77 */
				input-enable;          /* in zephyr/boards/infineon/cy8cproto_062_4343w/cy8cproto_062_4343w-pinctrl.dtsi:78 */
				phandle = < 0x10 >;    /* in zephyr/boards/infineon/cy8cproto_062_4343w/cy8cproto_062_4343w.dts:84 */
			};
		};

		/* node '/soc/scb@40600000' defined in zephyr/dts/arm/infineon/cat1a/psoc6_02/psoc6_02.dtsi:219 */
		scb0: scb@40600000 {
			compatible = "infineon,cat1-scb"; /* in zephyr/dts/arm/infineon/cat1a/psoc6_02/psoc6_02.dtsi:220 */
			reg = < 0x40600000 0x10000 >;     /* in zephyr/dts/arm/infineon/cat1a/psoc6_02/psoc6_02.dtsi:221 */
			#address-cells = < 0x1 >;         /* in zephyr/dts/arm/infineon/cat1a/psoc6_02/psoc6_02.dtsi:222 */
			#size-cells = < 0x0 >;            /* in zephyr/dts/arm/infineon/cat1a/psoc6_02/psoc6_02.dtsi:223 */
			interrupts = < 0x27 0x6 >;        /* in zephyr/dts/arm/infineon/cat1a/psoc6_02/psoc6_02.dtsi:224 */
			status = "disabled";              /* in zephyr/dts/arm/infineon/cat1a/psoc6_02/psoc6_02.dtsi:225 */
		};

		/* node '/soc/scb@40610000' defined in zephyr/dts/arm/infineon/cat1a/psoc6_02/psoc6_02.dtsi:228 */
		scb1: scb@40610000 {
			compatible = "infineon,cat1-scb"; /* in zephyr/dts/arm/infineon/cat1a/psoc6_02/psoc6_02.dtsi:229 */
			reg = < 0x40610000 0x10000 >;     /* in zephyr/dts/arm/infineon/cat1a/psoc6_02/psoc6_02.dtsi:230 */
			#address-cells = < 0x1 >;         /* in zephyr/dts/arm/infineon/cat1a/psoc6_02/psoc6_02.dtsi:231 */
			#size-cells = < 0x0 >;            /* in zephyr/dts/arm/infineon/cat1a/psoc6_02/psoc6_02.dtsi:232 */
			interrupts = < 0x28 0x6 >;        /* in zephyr/dts/arm/infineon/cat1a/psoc6_02/psoc6_02.dtsi:233 */
			status = "disabled";              /* in zephyr/dts/arm/infineon/cat1a/psoc6_02/psoc6_02.dtsi:234 */
		};

		/* node '/soc/scb@40620000' defined in zephyr/dts/arm/infineon/cat1a/psoc6_02/psoc6_02.dtsi:237 */
		scb2: uart2: scb@40620000 {
			reg = < 0x40620000 0x10000 >;                                                                  /* in zephyr/dts/arm/infineon/cat1a/psoc6_02/psoc6_02.dtsi:239 */
			#address-cells = < 0x1 >;                                                                      /* in zephyr/dts/arm/infineon/cat1a/psoc6_02/psoc6_02.dtsi:240 */
			#size-cells = < 0x0 >;                                                                         /* in zephyr/dts/arm/infineon/cat1a/psoc6_02/psoc6_02.dtsi:241 */
			interrupts = < 0x29 0x6 >;                                                                     /* in zephyr/dts/arm/infineon/cat1a/psoc6_02/psoc6_02.dtsi:242 */
			compatible = "infineon,cat1-uart";                                                             /* in zephyr/boards/infineon/cy8cproto_062_4343w/cy8cproto_062_4343w.dts:46 */
			status = "okay";                                                                               /* in zephyr/boards/infineon/cy8cproto_062_4343w/cy8cproto_062_4343w.dts:47 */
			current-speed = < 0x1c200 >;                                                                   /* in zephyr/boards/infineon/cy8cproto_062_4343w/cy8cproto_062_4343w.dts:52 */
			pinctrl-0 = < &p3_1_scb2_uart_tx &p3_0_scb2_uart_rx &p3_2_scb2_uart_rts &p3_3_scb2_uart_cts >; /* in zephyr/boards/infineon/cy8cproto_062_4343w/cy8cproto_062_4343w.dts:55 */
			pinctrl-names = "default";                                                                     /* in zephyr/boards/infineon/cy8cproto_062_4343w/cy8cproto_062_4343w.dts:56 */
			hw-flow-control;                                                                               /* in zephyr/boards/infineon/cy8cproto_062_4343w/cy8cproto_062_4343w.dts:59 */

			/* node '/soc/scb@40620000/bt_hci_uart' defined in zephyr/boards/infineon/cy8cproto_062_4343w/cy8cproto_062_4343w.dts:61 */
			bt_hci_uart: bt_hci_uart {
				compatible = "zephyr,bt-hci-uart"; /* in zephyr/boards/infineon/cy8cproto_062_4343w/cy8cproto_062_4343w.dts:62 */

				/* node '/soc/scb@40620000/bt_hci_uart/murata-1dx' defined in zephyr/boards/infineon/cy8cproto_062_4343w/cy8cproto_062_4343w.dts:64 */
				murata-1dx {
					status = "okay";                          /* in zephyr/boards/infineon/cy8cproto_062_4343w/cy8cproto_062_4343w.dts:65 */
					compatible = "infineon,cyw43xxx-bt-hci";  /* in zephyr/boards/infineon/cy8cproto_062_4343w/cy8cproto_062_4343w.dts:66 */
					bt-reg-on-gpios = < &gpio_prt3 0x4 0x0 >; /* in zephyr/boards/infineon/cy8cproto_062_4343w/cy8cproto_062_4343w.dts:67 */
					fw-download-speed = < 0x2dc6c0 >;         /* in zephyr/boards/infineon/cy8cproto_062_4343w/cy8cproto_062_4343w.dts:75 */
				};
			};
		};

		/* node '/soc/scb@40630000' defined in zephyr/dts/arm/infineon/cat1a/psoc6_02/psoc6_02.dtsi:246 */
		scb3: i2c3: scb@40630000 {
			reg = < 0x40630000 0x10000 >;                          /* in zephyr/dts/arm/infineon/cat1a/psoc6_02/psoc6_02.dtsi:248 */
			#address-cells = < 0x1 >;                              /* in zephyr/dts/arm/infineon/cat1a/psoc6_02/psoc6_02.dtsi:249 */
			#size-cells = < 0x0 >;                                 /* in zephyr/dts/arm/infineon/cat1a/psoc6_02/psoc6_02.dtsi:250 */
			interrupts = < 0x2a 0x6 >;                             /* in zephyr/dts/arm/infineon/cat1a/psoc6_02/psoc6_02.dtsi:251 */
			status = "disabled";                                   /* in zephyr/dts/arm/infineon/cat1a/psoc6_02/psoc6_02.dtsi:252 */
			compatible = "infineon,cat1-i2c";                      /* in zephyr/boards/infineon/cy8cproto_062_4343w/cy8cproto_062_4343w.dts:132 */
			pinctrl-0 = < &p6_0_scb3_i2c_scl &p6_1_scb3_i2c_sda >; /* in zephyr/boards/infineon/cy8cproto_062_4343w/cy8cproto_062_4343w.dts:135 */
			pinctrl-names = "default";                             /* in zephyr/boards/infineon/cy8cproto_062_4343w/cy8cproto_062_4343w.dts:136 */
		};

		/* node '/soc/scb@40640000' defined in zephyr/dts/arm/infineon/cat1a/psoc6_02/psoc6_02.dtsi:255 */
		scb4: scb@40640000 {
			compatible = "infineon,cat1-scb"; /* in zephyr/dts/arm/infineon/cat1a/psoc6_02/psoc6_02.dtsi:256 */
			reg = < 0x40640000 0x10000 >;     /* in zephyr/dts/arm/infineon/cat1a/psoc6_02/psoc6_02.dtsi:257 */
			#address-cells = < 0x1 >;         /* in zephyr/dts/arm/infineon/cat1a/psoc6_02/psoc6_02.dtsi:258 */
			#size-cells = < 0x0 >;            /* in zephyr/dts/arm/infineon/cat1a/psoc6_02/psoc6_02.dtsi:259 */
			interrupts = < 0x2b 0x6 >;        /* in zephyr/dts/arm/infineon/cat1a/psoc6_02/psoc6_02.dtsi:260 */
			status = "disabled";              /* in zephyr/dts/arm/infineon/cat1a/psoc6_02/psoc6_02.dtsi:261 */
		};

		/* node '/soc/scb@40650000' defined in zephyr/dts/arm/infineon/cat1a/psoc6_02/psoc6_02.dtsi:264 */
		scb5: uart5: scb@40650000 {
			reg = < 0x40650000 0x10000 >;                          /* in zephyr/dts/arm/infineon/cat1a/psoc6_02/psoc6_02.dtsi:266 */
			#address-cells = < 0x1 >;                              /* in zephyr/dts/arm/infineon/cat1a/psoc6_02/psoc6_02.dtsi:267 */
			#size-cells = < 0x0 >;                                 /* in zephyr/dts/arm/infineon/cat1a/psoc6_02/psoc6_02.dtsi:268 */
			interrupts = < 0x2c 0x6 >;                             /* in zephyr/dts/arm/infineon/cat1a/psoc6_02/psoc6_02.dtsi:269 */
			compatible = "infineon,cat1-uart";                     /* in zephyr/boards/infineon/cy8cproto_062_4343w/cy8cproto_062_4343w.dts:37 */
			status = "okay";                                       /* in zephyr/boards/infineon/cy8cproto_062_4343w/cy8cproto_062_4343w.dts:38 */
			current-speed = < 0x1c200 >;                           /* in zephyr/boards/infineon/cy8cproto_062_4343w/cy8cproto_062_4343w.dts:39 */
			pinctrl-0 = < &p5_1_scb5_uart_tx &p5_0_scb5_uart_rx >; /* in zephyr/boards/infineon/cy8cproto_062_4343w/cy8cproto_062_4343w.dts:41 */
			pinctrl-names = "default";                             /* in zephyr/boards/infineon/cy8cproto_062_4343w/cy8cproto_062_4343w.dts:42 */
		};

		/* node '/soc/scb@40660000' defined in zephyr/dts/arm/infineon/cat1a/psoc6_02/psoc6_02.dtsi:273 */
		scb6: scb@40660000 {
			compatible = "infineon,cat1-scb"; /* in zephyr/dts/arm/infineon/cat1a/psoc6_02/psoc6_02.dtsi:274 */
			reg = < 0x40660000 0x10000 >;     /* in zephyr/dts/arm/infineon/cat1a/psoc6_02/psoc6_02.dtsi:275 */
			#address-cells = < 0x1 >;         /* in zephyr/dts/arm/infineon/cat1a/psoc6_02/psoc6_02.dtsi:276 */
			#size-cells = < 0x0 >;            /* in zephyr/dts/arm/infineon/cat1a/psoc6_02/psoc6_02.dtsi:277 */
			interrupts = < 0x2d 0x6 >;        /* in zephyr/dts/arm/infineon/cat1a/psoc6_02/psoc6_02.dtsi:278 */
			status = "disabled";              /* in zephyr/dts/arm/infineon/cat1a/psoc6_02/psoc6_02.dtsi:279 */
		};

		/* node '/soc/scb@40670000' defined in zephyr/dts/arm/infineon/cat1a/psoc6_02/psoc6_02.dtsi:282 */
		scb7: scb@40670000 {
			compatible = "infineon,cat1-scb"; /* in zephyr/dts/arm/infineon/cat1a/psoc6_02/psoc6_02.dtsi:283 */
			reg = < 0x40670000 0x10000 >;     /* in zephyr/dts/arm/infineon/cat1a/psoc6_02/psoc6_02.dtsi:284 */
			#address-cells = < 0x1 >;         /* in zephyr/dts/arm/infineon/cat1a/psoc6_02/psoc6_02.dtsi:285 */
			#size-cells = < 0x0 >;            /* in zephyr/dts/arm/infineon/cat1a/psoc6_02/psoc6_02.dtsi:286 */
			interrupts = < 0x2e 0x6 >;        /* in zephyr/dts/arm/infineon/cat1a/psoc6_02/psoc6_02.dtsi:287 */
			status = "disabled";              /* in zephyr/dts/arm/infineon/cat1a/psoc6_02/psoc6_02.dtsi:288 */
		};

		/* node '/soc/scb@40680000' defined in zephyr/dts/arm/infineon/cat1a/psoc6_02/psoc6_02.dtsi:291 */
		scb8: scb@40680000 {
			compatible = "infineon,cat1-scb"; /* in zephyr/dts/arm/infineon/cat1a/psoc6_02/psoc6_02.dtsi:292 */
			reg = < 0x40680000 0x10000 >;     /* in zephyr/dts/arm/infineon/cat1a/psoc6_02/psoc6_02.dtsi:293 */
			#address-cells = < 0x1 >;         /* in zephyr/dts/arm/infineon/cat1a/psoc6_02/psoc6_02.dtsi:294 */
			#size-cells = < 0x0 >;            /* in zephyr/dts/arm/infineon/cat1a/psoc6_02/psoc6_02.dtsi:295 */
			interrupts = < 0x12 0x6 >;        /* in zephyr/dts/arm/infineon/cat1a/psoc6_02/psoc6_02.dtsi:296 */
			status = "disabled";              /* in zephyr/dts/arm/infineon/cat1a/psoc6_02/psoc6_02.dtsi:297 */
		};

		/* node '/soc/scb@40690000' defined in zephyr/dts/arm/infineon/cat1a/psoc6_02/psoc6_02.dtsi:300 */
		scb9: scb@40690000 {
			compatible = "infineon,cat1-scb"; /* in zephyr/dts/arm/infineon/cat1a/psoc6_02/psoc6_02.dtsi:301 */
			reg = < 0x40690000 0x10000 >;     /* in zephyr/dts/arm/infineon/cat1a/psoc6_02/psoc6_02.dtsi:302 */
			#address-cells = < 0x1 >;         /* in zephyr/dts/arm/infineon/cat1a/psoc6_02/psoc6_02.dtsi:303 */
			#size-cells = < 0x0 >;            /* in zephyr/dts/arm/infineon/cat1a/psoc6_02/psoc6_02.dtsi:304 */
			interrupts = < 0x2f 0x6 >;        /* in zephyr/dts/arm/infineon/cat1a/psoc6_02/psoc6_02.dtsi:305 */
			status = "disabled";              /* in zephyr/dts/arm/infineon/cat1a/psoc6_02/psoc6_02.dtsi:306 */
		};

		/* node '/soc/scb@406a0000' defined in zephyr/dts/arm/infineon/cat1a/psoc6_02/psoc6_02.dtsi:309 */
		scb10: scb@406a0000 {
			compatible = "infineon,cat1-scb"; /* in zephyr/dts/arm/infineon/cat1a/psoc6_02/psoc6_02.dtsi:310 */
			reg = < 0x406a0000 0x10000 >;     /* in zephyr/dts/arm/infineon/cat1a/psoc6_02/psoc6_02.dtsi:311 */
			#address-cells = < 0x1 >;         /* in zephyr/dts/arm/infineon/cat1a/psoc6_02/psoc6_02.dtsi:312 */
			#size-cells = < 0x0 >;            /* in zephyr/dts/arm/infineon/cat1a/psoc6_02/psoc6_02.dtsi:313 */
			interrupts = < 0x30 0x6 >;        /* in zephyr/dts/arm/infineon/cat1a/psoc6_02/psoc6_02.dtsi:314 */
			status = "disabled";              /* in zephyr/dts/arm/infineon/cat1a/psoc6_02/psoc6_02.dtsi:315 */
		};

		/* node '/soc/scb@406b0000' defined in zephyr/dts/arm/infineon/cat1a/psoc6_02/psoc6_02.dtsi:318 */
		scb11: scb@406b0000 {
			compatible = "infineon,cat1-scb"; /* in zephyr/dts/arm/infineon/cat1a/psoc6_02/psoc6_02.dtsi:319 */
			reg = < 0x406b0000 0x10000 >;     /* in zephyr/dts/arm/infineon/cat1a/psoc6_02/psoc6_02.dtsi:320 */
			#address-cells = < 0x1 >;         /* in zephyr/dts/arm/infineon/cat1a/psoc6_02/psoc6_02.dtsi:321 */
			#size-cells = < 0x0 >;            /* in zephyr/dts/arm/infineon/cat1a/psoc6_02/psoc6_02.dtsi:322 */
			interrupts = < 0x31 0x6 >;        /* in zephyr/dts/arm/infineon/cat1a/psoc6_02/psoc6_02.dtsi:323 */
			status = "disabled";              /* in zephyr/dts/arm/infineon/cat1a/psoc6_02/psoc6_02.dtsi:324 */
		};

		/* node '/soc/scb@406c0000' defined in zephyr/dts/arm/infineon/cat1a/psoc6_02/psoc6_02.dtsi:327 */
		scb12: scb@406c0000 {
			compatible = "infineon,cat1-scb"; /* in zephyr/dts/arm/infineon/cat1a/psoc6_02/psoc6_02.dtsi:328 */
			reg = < 0x406c0000 0x10000 >;     /* in zephyr/dts/arm/infineon/cat1a/psoc6_02/psoc6_02.dtsi:329 */
			#address-cells = < 0x1 >;         /* in zephyr/dts/arm/infineon/cat1a/psoc6_02/psoc6_02.dtsi:330 */
			#size-cells = < 0x0 >;            /* in zephyr/dts/arm/infineon/cat1a/psoc6_02/psoc6_02.dtsi:331 */
			interrupts = < 0x32 0x6 >;        /* in zephyr/dts/arm/infineon/cat1a/psoc6_02/psoc6_02.dtsi:332 */
			status = "disabled";              /* in zephyr/dts/arm/infineon/cat1a/psoc6_02/psoc6_02.dtsi:333 */
		};

		/* node '/soc/adc@409d0000' defined in zephyr/dts/arm/infineon/cat1a/psoc6_02/psoc6_02.dtsi:336 */
		adc0: adc@409d0000 {
			compatible = "infineon,cat1-adc"; /* in zephyr/dts/arm/infineon/cat1a/psoc6_02/psoc6_02.dtsi:337 */
			reg = < 0x409d0000 0x10000 >;     /* in zephyr/dts/arm/infineon/cat1a/psoc6_02/psoc6_02.dtsi:338 */
			interrupts = < 0x9b 0x6 >;        /* in zephyr/dts/arm/infineon/cat1a/psoc6_02/psoc6_02.dtsi:339 */
			status = "disabled";              /* in zephyr/dts/arm/infineon/cat1a/psoc6_02/psoc6_02.dtsi:340 */
			#io-channel-cells = < 0x1 >;      /* in zephyr/dts/arm/infineon/cat1a/psoc6_02/psoc6_02.dtsi:341 */
		};

		/* node '/soc/watchdog@40260180' defined in zephyr/dts/arm/infineon/cat1a/psoc6_02/psoc6_02.dtsi:344 */
		watchdog0: watchdog@40260180 {
			compatible = "infineon,cat1-watchdog"; /* in zephyr/dts/arm/infineon/cat1a/psoc6_02/psoc6_02.dtsi:345 */
			reg = < 0x40260180 0xc >;              /* in zephyr/dts/arm/infineon/cat1a/psoc6_02/psoc6_02.dtsi:346 */
			interrupts = < 0x16 0x6 >;             /* in zephyr/dts/arm/infineon/cat1a/psoc6_02/psoc6_02.dtsi:347 */
			status = "okay";                       /* in zephyr/boards/infineon/cy8cproto_062_4343w/cy8cproto_062_4343w.dts:140 */
		};

		/* node '/soc/counter@40380100' defined in zephyr/dts/arm/infineon/cat1a/psoc6_02/psoc6_02.dtsi:351 */
		counter0_0: counter@40380100 {
			compatible = "infineon,cat1-counter"; /* in zephyr/dts/arm/infineon/cat1a/psoc6_02/psoc6_02.dtsi:352 */
			reg = < 0x40380100 0x40 >;            /* in zephyr/dts/arm/infineon/cat1a/psoc6_02/psoc6_02.dtsi:353 */
			interrupts = < 0x7b 0x6 >;            /* in zephyr/dts/arm/infineon/cat1a/psoc6_02/psoc6_02.dtsi:354 */
			resolution = < 0x20 >;                /* in zephyr/dts/arm/infineon/cat1a/psoc6_02/psoc6_02.dtsi:355 */
			status = "okay";                      /* in zephyr/boards/infineon/cy8cproto_062_4343w/cy8cproto_062_4343w.dts:33 */
		};

		/* node '/soc/counter@40380140' defined in zephyr/dts/arm/infineon/cat1a/psoc6_02/psoc6_02.dtsi:359 */
		counter0_1: counter@40380140 {
			compatible = "infineon,cat1-counter"; /* in zephyr/dts/arm/infineon/cat1a/psoc6_02/psoc6_02.dtsi:360 */
			reg = < 0x40380140 0x40 >;            /* in zephyr/dts/arm/infineon/cat1a/psoc6_02/psoc6_02.dtsi:361 */
			interrupts = < 0x7c 0x6 >;            /* in zephyr/dts/arm/infineon/cat1a/psoc6_02/psoc6_02.dtsi:362 */
			resolution = < 0x20 >;                /* in zephyr/dts/arm/infineon/cat1a/psoc6_02/psoc6_02.dtsi:363 */
			status = "disabled";                  /* in zephyr/dts/arm/infineon/cat1a/psoc6_02/psoc6_02.dtsi:364 */
		};

		/* node '/soc/counter@40380180' defined in zephyr/dts/arm/infineon/cat1a/psoc6_02/psoc6_02.dtsi:367 */
		counter0_2: counter@40380180 {
			compatible = "infineon,cat1-counter"; /* in zephyr/dts/arm/infineon/cat1a/psoc6_02/psoc6_02.dtsi:368 */
			reg = < 0x40380180 0x40 >;            /* in zephyr/dts/arm/infineon/cat1a/psoc6_02/psoc6_02.dtsi:369 */
			interrupts = < 0x7d 0x6 >;            /* in zephyr/dts/arm/infineon/cat1a/psoc6_02/psoc6_02.dtsi:370 */
			resolution = < 0x20 >;                /* in zephyr/dts/arm/infineon/cat1a/psoc6_02/psoc6_02.dtsi:371 */
			status = "disabled";                  /* in zephyr/dts/arm/infineon/cat1a/psoc6_02/psoc6_02.dtsi:372 */
		};

		/* node '/soc/counter@403801c0' defined in zephyr/dts/arm/infineon/cat1a/psoc6_02/psoc6_02.dtsi:375 */
		counter0_3: counter@403801c0 {
			compatible = "infineon,cat1-counter"; /* in zephyr/dts/arm/infineon/cat1a/psoc6_02/psoc6_02.dtsi:376 */
			reg = < 0x403801c0 0x40 >;            /* in zephyr/dts/arm/infineon/cat1a/psoc6_02/psoc6_02.dtsi:377 */
			interrupts = < 0x7e 0x6 >;            /* in zephyr/dts/arm/infineon/cat1a/psoc6_02/psoc6_02.dtsi:378 */
			resolution = < 0x20 >;                /* in zephyr/dts/arm/infineon/cat1a/psoc6_02/psoc6_02.dtsi:379 */
			status = "disabled";                  /* in zephyr/dts/arm/infineon/cat1a/psoc6_02/psoc6_02.dtsi:380 */
		};

		/* node '/soc/counter@40380200' defined in zephyr/dts/arm/infineon/cat1a/psoc6_02/psoc6_02.dtsi:383 */
		counter0_4: counter@40380200 {
			compatible = "infineon,cat1-counter"; /* in zephyr/dts/arm/infineon/cat1a/psoc6_02/psoc6_02.dtsi:384 */
			reg = < 0x40380200 0x40 >;            /* in zephyr/dts/arm/infineon/cat1a/psoc6_02/psoc6_02.dtsi:385 */
			interrupts = < 0x7f 0x6 >;            /* in zephyr/dts/arm/infineon/cat1a/psoc6_02/psoc6_02.dtsi:386 */
			resolution = < 0x20 >;                /* in zephyr/dts/arm/infineon/cat1a/psoc6_02/psoc6_02.dtsi:387 */
			status = "disabled";                  /* in zephyr/dts/arm/infineon/cat1a/psoc6_02/psoc6_02.dtsi:388 */
		};

		/* node '/soc/counter@40380240' defined in zephyr/dts/arm/infineon/cat1a/psoc6_02/psoc6_02.dtsi:391 */
		counter0_5: counter@40380240 {
			compatible = "infineon,cat1-counter"; /* in zephyr/dts/arm/infineon/cat1a/psoc6_02/psoc6_02.dtsi:392 */
			reg = < 0x40380240 0x40 >;            /* in zephyr/dts/arm/infineon/cat1a/psoc6_02/psoc6_02.dtsi:393 */
			interrupts = < 0x80 0x6 >;            /* in zephyr/dts/arm/infineon/cat1a/psoc6_02/psoc6_02.dtsi:394 */
			resolution = < 0x20 >;                /* in zephyr/dts/arm/infineon/cat1a/psoc6_02/psoc6_02.dtsi:395 */
			status = "disabled";                  /* in zephyr/dts/arm/infineon/cat1a/psoc6_02/psoc6_02.dtsi:396 */
		};

		/* node '/soc/counter@40380280' defined in zephyr/dts/arm/infineon/cat1a/psoc6_02/psoc6_02.dtsi:399 */
		counter0_6: counter@40380280 {
			compatible = "infineon,cat1-counter"; /* in zephyr/dts/arm/infineon/cat1a/psoc6_02/psoc6_02.dtsi:400 */
			reg = < 0x40380280 0x40 >;            /* in zephyr/dts/arm/infineon/cat1a/psoc6_02/psoc6_02.dtsi:401 */
			interrupts = < 0x81 0x6 >;            /* in zephyr/dts/arm/infineon/cat1a/psoc6_02/psoc6_02.dtsi:402 */
			resolution = < 0x20 >;                /* in zephyr/dts/arm/infineon/cat1a/psoc6_02/psoc6_02.dtsi:403 */
			status = "disabled";                  /* in zephyr/dts/arm/infineon/cat1a/psoc6_02/psoc6_02.dtsi:404 */
		};

		/* node '/soc/counter@403802c0' defined in zephyr/dts/arm/infineon/cat1a/psoc6_02/psoc6_02.dtsi:407 */
		counter0_7: counter@403802c0 {
			compatible = "infineon,cat1-counter"; /* in zephyr/dts/arm/infineon/cat1a/psoc6_02/psoc6_02.dtsi:408 */
			reg = < 0x403802c0 0x40 >;            /* in zephyr/dts/arm/infineon/cat1a/psoc6_02/psoc6_02.dtsi:409 */
			interrupts = < 0x82 0x6 >;            /* in zephyr/dts/arm/infineon/cat1a/psoc6_02/psoc6_02.dtsi:410 */
			resolution = < 0x20 >;                /* in zephyr/dts/arm/infineon/cat1a/psoc6_02/psoc6_02.dtsi:411 */
			status = "disabled";                  /* in zephyr/dts/arm/infineon/cat1a/psoc6_02/psoc6_02.dtsi:412 */
		};

		/* node '/soc/counter@40390100' defined in zephyr/dts/arm/infineon/cat1a/psoc6_02/psoc6_02.dtsi:415 */
		counter1_0: counter@40390100 {
			compatible = "infineon,cat1-counter"; /* in zephyr/dts/arm/infineon/cat1a/psoc6_02/psoc6_02.dtsi:416 */
			reg = < 0x40390100 0x40 >;            /* in zephyr/dts/arm/infineon/cat1a/psoc6_02/psoc6_02.dtsi:417 */
			interrupts = < 0x83 0x6 >;            /* in zephyr/dts/arm/infineon/cat1a/psoc6_02/psoc6_02.dtsi:418 */
			resolution = < 0x10 >;                /* in zephyr/dts/arm/infineon/cat1a/psoc6_02/psoc6_02.dtsi:419 */
			status = "disabled";                  /* in zephyr/dts/arm/infineon/cat1a/psoc6_02/psoc6_02.dtsi:420 */
		};

		/* node '/soc/counter@40390140' defined in zephyr/dts/arm/infineon/cat1a/psoc6_02/psoc6_02.dtsi:423 */
		counter1_1: counter@40390140 {
			compatible = "infineon,cat1-counter"; /* in zephyr/dts/arm/infineon/cat1a/psoc6_02/psoc6_02.dtsi:424 */
			reg = < 0x40390140 0x40 >;            /* in zephyr/dts/arm/infineon/cat1a/psoc6_02/psoc6_02.dtsi:425 */
			interrupts = < 0x84 0x6 >;            /* in zephyr/dts/arm/infineon/cat1a/psoc6_02/psoc6_02.dtsi:426 */
			resolution = < 0x10 >;                /* in zephyr/dts/arm/infineon/cat1a/psoc6_02/psoc6_02.dtsi:427 */
			status = "disabled";                  /* in zephyr/dts/arm/infineon/cat1a/psoc6_02/psoc6_02.dtsi:428 */
		};

		/* node '/soc/counter@40390180' defined in zephyr/dts/arm/infineon/cat1a/psoc6_02/psoc6_02.dtsi:431 */
		counter1_2: counter@40390180 {
			compatible = "infineon,cat1-counter"; /* in zephyr/dts/arm/infineon/cat1a/psoc6_02/psoc6_02.dtsi:432 */
			reg = < 0x40390180 0x40 >;            /* in zephyr/dts/arm/infineon/cat1a/psoc6_02/psoc6_02.dtsi:433 */
			interrupts = < 0x85 0x6 >;            /* in zephyr/dts/arm/infineon/cat1a/psoc6_02/psoc6_02.dtsi:434 */
			resolution = < 0x10 >;                /* in zephyr/dts/arm/infineon/cat1a/psoc6_02/psoc6_02.dtsi:435 */
			status = "disabled";                  /* in zephyr/dts/arm/infineon/cat1a/psoc6_02/psoc6_02.dtsi:436 */
		};

		/* node '/soc/counter@403901c0' defined in zephyr/dts/arm/infineon/cat1a/psoc6_02/psoc6_02.dtsi:439 */
		counter1_3: counter@403901c0 {
			compatible = "infineon,cat1-counter"; /* in zephyr/dts/arm/infineon/cat1a/psoc6_02/psoc6_02.dtsi:440 */
			reg = < 0x403901c0 0x40 >;            /* in zephyr/dts/arm/infineon/cat1a/psoc6_02/psoc6_02.dtsi:441 */
			interrupts = < 0x86 0x6 >;            /* in zephyr/dts/arm/infineon/cat1a/psoc6_02/psoc6_02.dtsi:442 */
			resolution = < 0x10 >;                /* in zephyr/dts/arm/infineon/cat1a/psoc6_02/psoc6_02.dtsi:443 */
			status = "disabled";                  /* in zephyr/dts/arm/infineon/cat1a/psoc6_02/psoc6_02.dtsi:444 */
		};

		/* node '/soc/counter@40390200' defined in zephyr/dts/arm/infineon/cat1a/psoc6_02/psoc6_02.dtsi:447 */
		counter1_4: counter@40390200 {
			compatible = "infineon,cat1-counter"; /* in zephyr/dts/arm/infineon/cat1a/psoc6_02/psoc6_02.dtsi:448 */
			reg = < 0x40390200 0x40 >;            /* in zephyr/dts/arm/infineon/cat1a/psoc6_02/psoc6_02.dtsi:449 */
			interrupts = < 0x87 0x6 >;            /* in zephyr/dts/arm/infineon/cat1a/psoc6_02/psoc6_02.dtsi:450 */
			resolution = < 0x10 >;                /* in zephyr/dts/arm/infineon/cat1a/psoc6_02/psoc6_02.dtsi:451 */
			status = "disabled";                  /* in zephyr/dts/arm/infineon/cat1a/psoc6_02/psoc6_02.dtsi:452 */
		};

		/* node '/soc/counter@40390240' defined in zephyr/dts/arm/infineon/cat1a/psoc6_02/psoc6_02.dtsi:455 */
		counter1_5: counter@40390240 {
			compatible = "infineon,cat1-counter"; /* in zephyr/dts/arm/infineon/cat1a/psoc6_02/psoc6_02.dtsi:456 */
			reg = < 0x40390240 0x40 >;            /* in zephyr/dts/arm/infineon/cat1a/psoc6_02/psoc6_02.dtsi:457 */
			interrupts = < 0x88 0x6 >;            /* in zephyr/dts/arm/infineon/cat1a/psoc6_02/psoc6_02.dtsi:458 */
			resolution = < 0x10 >;                /* in zephyr/dts/arm/infineon/cat1a/psoc6_02/psoc6_02.dtsi:459 */
			status = "disabled";                  /* in zephyr/dts/arm/infineon/cat1a/psoc6_02/psoc6_02.dtsi:460 */
		};

		/* node '/soc/counter@40390280' defined in zephyr/dts/arm/infineon/cat1a/psoc6_02/psoc6_02.dtsi:463 */
		counter1_6: counter@40390280 {
			compatible = "infineon,cat1-counter"; /* in zephyr/dts/arm/infineon/cat1a/psoc6_02/psoc6_02.dtsi:464 */
			reg = < 0x40390280 0x40 >;            /* in zephyr/dts/arm/infineon/cat1a/psoc6_02/psoc6_02.dtsi:465 */
			interrupts = < 0x89 0x6 >;            /* in zephyr/dts/arm/infineon/cat1a/psoc6_02/psoc6_02.dtsi:466 */
			resolution = < 0x10 >;                /* in zephyr/dts/arm/infineon/cat1a/psoc6_02/psoc6_02.dtsi:467 */
			status = "disabled";                  /* in zephyr/dts/arm/infineon/cat1a/psoc6_02/psoc6_02.dtsi:468 */
		};

		/* node '/soc/counter@403902c0' defined in zephyr/dts/arm/infineon/cat1a/psoc6_02/psoc6_02.dtsi:471 */
		counter1_7: counter@403902c0 {
			compatible = "infineon,cat1-counter"; /* in zephyr/dts/arm/infineon/cat1a/psoc6_02/psoc6_02.dtsi:472 */
			reg = < 0x403902c0 0x40 >;            /* in zephyr/dts/arm/infineon/cat1a/psoc6_02/psoc6_02.dtsi:473 */
			interrupts = < 0x8a 0x6 >;            /* in zephyr/dts/arm/infineon/cat1a/psoc6_02/psoc6_02.dtsi:474 */
			resolution = < 0x10 >;                /* in zephyr/dts/arm/infineon/cat1a/psoc6_02/psoc6_02.dtsi:475 */
			status = "disabled";                  /* in zephyr/dts/arm/infineon/cat1a/psoc6_02/psoc6_02.dtsi:476 */
		};

		/* node '/soc/counter@40390300' defined in zephyr/dts/arm/infineon/cat1a/psoc6_02/psoc6_02.dtsi:479 */
		counter1_8: counter@40390300 {
			compatible = "infineon,cat1-counter"; /* in zephyr/dts/arm/infineon/cat1a/psoc6_02/psoc6_02.dtsi:480 */
			reg = < 0x40390300 0x40 >;            /* in zephyr/dts/arm/infineon/cat1a/psoc6_02/psoc6_02.dtsi:481 */
			interrupts = < 0x8b 0x6 >;            /* in zephyr/dts/arm/infineon/cat1a/psoc6_02/psoc6_02.dtsi:482 */
			resolution = < 0x10 >;                /* in zephyr/dts/arm/infineon/cat1a/psoc6_02/psoc6_02.dtsi:483 */
			status = "disabled";                  /* in zephyr/dts/arm/infineon/cat1a/psoc6_02/psoc6_02.dtsi:484 */
		};

		/* node '/soc/counter@40390340' defined in zephyr/dts/arm/infineon/cat1a/psoc6_02/psoc6_02.dtsi:487 */
		counter1_9: counter@40390340 {
			compatible = "infineon,cat1-counter"; /* in zephyr/dts/arm/infineon/cat1a/psoc6_02/psoc6_02.dtsi:488 */
			reg = < 0x40390340 0x40 >;            /* in zephyr/dts/arm/infineon/cat1a/psoc6_02/psoc6_02.dtsi:489 */
			interrupts = < 0x8c 0x6 >;            /* in zephyr/dts/arm/infineon/cat1a/psoc6_02/psoc6_02.dtsi:490 */
			resolution = < 0x10 >;                /* in zephyr/dts/arm/infineon/cat1a/psoc6_02/psoc6_02.dtsi:491 */
			status = "disabled";                  /* in zephyr/dts/arm/infineon/cat1a/psoc6_02/psoc6_02.dtsi:492 */
		};

		/* node '/soc/counter@40390380' defined in zephyr/dts/arm/infineon/cat1a/psoc6_02/psoc6_02.dtsi:495 */
		counter1_10: counter@40390380 {
			compatible = "infineon,cat1-counter"; /* in zephyr/dts/arm/infineon/cat1a/psoc6_02/psoc6_02.dtsi:496 */
			reg = < 0x40390380 0x40 >;            /* in zephyr/dts/arm/infineon/cat1a/psoc6_02/psoc6_02.dtsi:497 */
			interrupts = < 0x8d 0x6 >;            /* in zephyr/dts/arm/infineon/cat1a/psoc6_02/psoc6_02.dtsi:498 */
			resolution = < 0x10 >;                /* in zephyr/dts/arm/infineon/cat1a/psoc6_02/psoc6_02.dtsi:499 */
			status = "disabled";                  /* in zephyr/dts/arm/infineon/cat1a/psoc6_02/psoc6_02.dtsi:500 */
		};

		/* node '/soc/counter@403903c0' defined in zephyr/dts/arm/infineon/cat1a/psoc6_02/psoc6_02.dtsi:503 */
		counter1_11: counter@403903c0 {
			compatible = "infineon,cat1-counter"; /* in zephyr/dts/arm/infineon/cat1a/psoc6_02/psoc6_02.dtsi:504 */
			reg = < 0x403903c0 0x40 >;            /* in zephyr/dts/arm/infineon/cat1a/psoc6_02/psoc6_02.dtsi:505 */
			interrupts = < 0x8e 0x6 >;            /* in zephyr/dts/arm/infineon/cat1a/psoc6_02/psoc6_02.dtsi:506 */
			resolution = < 0x10 >;                /* in zephyr/dts/arm/infineon/cat1a/psoc6_02/psoc6_02.dtsi:507 */
			status = "disabled";                  /* in zephyr/dts/arm/infineon/cat1a/psoc6_02/psoc6_02.dtsi:508 */
		};

		/* node '/soc/counter@40390400' defined in zephyr/dts/arm/infineon/cat1a/psoc6_02/psoc6_02.dtsi:511 */
		counter1_12: counter@40390400 {
			compatible = "infineon,cat1-counter"; /* in zephyr/dts/arm/infineon/cat1a/psoc6_02/psoc6_02.dtsi:512 */
			reg = < 0x40390400 0x40 >;            /* in zephyr/dts/arm/infineon/cat1a/psoc6_02/psoc6_02.dtsi:513 */
			interrupts = < 0x8f 0x6 >;            /* in zephyr/dts/arm/infineon/cat1a/psoc6_02/psoc6_02.dtsi:514 */
			resolution = < 0x10 >;                /* in zephyr/dts/arm/infineon/cat1a/psoc6_02/psoc6_02.dtsi:515 */
			status = "disabled";                  /* in zephyr/dts/arm/infineon/cat1a/psoc6_02/psoc6_02.dtsi:516 */
		};

		/* node '/soc/counter@40390440' defined in zephyr/dts/arm/infineon/cat1a/psoc6_02/psoc6_02.dtsi:519 */
		counter1_13: counter@40390440 {
			compatible = "infineon,cat1-counter"; /* in zephyr/dts/arm/infineon/cat1a/psoc6_02/psoc6_02.dtsi:520 */
			reg = < 0x40390440 0x40 >;            /* in zephyr/dts/arm/infineon/cat1a/psoc6_02/psoc6_02.dtsi:521 */
			interrupts = < 0x90 0x6 >;            /* in zephyr/dts/arm/infineon/cat1a/psoc6_02/psoc6_02.dtsi:522 */
			resolution = < 0x10 >;                /* in zephyr/dts/arm/infineon/cat1a/psoc6_02/psoc6_02.dtsi:523 */
			status = "disabled";                  /* in zephyr/dts/arm/infineon/cat1a/psoc6_02/psoc6_02.dtsi:524 */
		};

		/* node '/soc/counter@40390480' defined in zephyr/dts/arm/infineon/cat1a/psoc6_02/psoc6_02.dtsi:527 */
		counter1_14: counter@40390480 {
			compatible = "infineon,cat1-counter"; /* in zephyr/dts/arm/infineon/cat1a/psoc6_02/psoc6_02.dtsi:528 */
			reg = < 0x40390480 0x40 >;            /* in zephyr/dts/arm/infineon/cat1a/psoc6_02/psoc6_02.dtsi:529 */
			interrupts = < 0x91 0x6 >;            /* in zephyr/dts/arm/infineon/cat1a/psoc6_02/psoc6_02.dtsi:530 */
			resolution = < 0x10 >;                /* in zephyr/dts/arm/infineon/cat1a/psoc6_02/psoc6_02.dtsi:531 */
			status = "disabled";                  /* in zephyr/dts/arm/infineon/cat1a/psoc6_02/psoc6_02.dtsi:532 */
		};

		/* node '/soc/counter@403904c0' defined in zephyr/dts/arm/infineon/cat1a/psoc6_02/psoc6_02.dtsi:535 */
		counter1_15: counter@403904c0 {
			compatible = "infineon,cat1-counter"; /* in zephyr/dts/arm/infineon/cat1a/psoc6_02/psoc6_02.dtsi:536 */
			reg = < 0x403904c0 0x40 >;            /* in zephyr/dts/arm/infineon/cat1a/psoc6_02/psoc6_02.dtsi:537 */
			interrupts = < 0x92 0x6 >;            /* in zephyr/dts/arm/infineon/cat1a/psoc6_02/psoc6_02.dtsi:538 */
			resolution = < 0x10 >;                /* in zephyr/dts/arm/infineon/cat1a/psoc6_02/psoc6_02.dtsi:539 */
			status = "disabled";                  /* in zephyr/dts/arm/infineon/cat1a/psoc6_02/psoc6_02.dtsi:540 */
		};

		/* node '/soc/counter@40390500' defined in zephyr/dts/arm/infineon/cat1a/psoc6_02/psoc6_02.dtsi:543 */
		counter1_16: counter@40390500 {
			compatible = "infineon,cat1-counter"; /* in zephyr/dts/arm/infineon/cat1a/psoc6_02/psoc6_02.dtsi:544 */
			reg = < 0x40390500 0x40 >;            /* in zephyr/dts/arm/infineon/cat1a/psoc6_02/psoc6_02.dtsi:545 */
			interrupts = < 0x93 0x6 >;            /* in zephyr/dts/arm/infineon/cat1a/psoc6_02/psoc6_02.dtsi:546 */
			resolution = < 0x10 >;                /* in zephyr/dts/arm/infineon/cat1a/psoc6_02/psoc6_02.dtsi:547 */
			status = "disabled";                  /* in zephyr/dts/arm/infineon/cat1a/psoc6_02/psoc6_02.dtsi:548 */
		};

		/* node '/soc/counter@40390540' defined in zephyr/dts/arm/infineon/cat1a/psoc6_02/psoc6_02.dtsi:551 */
		counter1_17: counter@40390540 {
			compatible = "infineon,cat1-counter"; /* in zephyr/dts/arm/infineon/cat1a/psoc6_02/psoc6_02.dtsi:552 */
			reg = < 0x40390540 0x40 >;            /* in zephyr/dts/arm/infineon/cat1a/psoc6_02/psoc6_02.dtsi:553 */
			interrupts = < 0x94 0x6 >;            /* in zephyr/dts/arm/infineon/cat1a/psoc6_02/psoc6_02.dtsi:554 */
			resolution = < 0x10 >;                /* in zephyr/dts/arm/infineon/cat1a/psoc6_02/psoc6_02.dtsi:555 */
			status = "disabled";                  /* in zephyr/dts/arm/infineon/cat1a/psoc6_02/psoc6_02.dtsi:556 */
		};

		/* node '/soc/counter@40390580' defined in zephyr/dts/arm/infineon/cat1a/psoc6_02/psoc6_02.dtsi:559 */
		counter1_18: counter@40390580 {
			compatible = "infineon,cat1-counter"; /* in zephyr/dts/arm/infineon/cat1a/psoc6_02/psoc6_02.dtsi:560 */
			reg = < 0x40390580 0x40 >;            /* in zephyr/dts/arm/infineon/cat1a/psoc6_02/psoc6_02.dtsi:561 */
			interrupts = < 0x95 0x6 >;            /* in zephyr/dts/arm/infineon/cat1a/psoc6_02/psoc6_02.dtsi:562 */
			resolution = < 0x10 >;                /* in zephyr/dts/arm/infineon/cat1a/psoc6_02/psoc6_02.dtsi:563 */
			status = "disabled";                  /* in zephyr/dts/arm/infineon/cat1a/psoc6_02/psoc6_02.dtsi:564 */
		};

		/* node '/soc/counter@403905c0' defined in zephyr/dts/arm/infineon/cat1a/psoc6_02/psoc6_02.dtsi:567 */
		counter1_19: counter@403905c0 {
			compatible = "infineon,cat1-counter"; /* in zephyr/dts/arm/infineon/cat1a/psoc6_02/psoc6_02.dtsi:568 */
			reg = < 0x403905c0 0x40 >;            /* in zephyr/dts/arm/infineon/cat1a/psoc6_02/psoc6_02.dtsi:569 */
			interrupts = < 0x96 0x6 >;            /* in zephyr/dts/arm/infineon/cat1a/psoc6_02/psoc6_02.dtsi:570 */
			resolution = < 0x10 >;                /* in zephyr/dts/arm/infineon/cat1a/psoc6_02/psoc6_02.dtsi:571 */
			status = "disabled";                  /* in zephyr/dts/arm/infineon/cat1a/psoc6_02/psoc6_02.dtsi:572 */
		};

		/* node '/soc/counter@40390600' defined in zephyr/dts/arm/infineon/cat1a/psoc6_02/psoc6_02.dtsi:575 */
		counter1_20: counter@40390600 {
			compatible = "infineon,cat1-counter"; /* in zephyr/dts/arm/infineon/cat1a/psoc6_02/psoc6_02.dtsi:576 */
			reg = < 0x40390600 0x40 >;            /* in zephyr/dts/arm/infineon/cat1a/psoc6_02/psoc6_02.dtsi:577 */
			interrupts = < 0x97 0x6 >;            /* in zephyr/dts/arm/infineon/cat1a/psoc6_02/psoc6_02.dtsi:578 */
			resolution = < 0x10 >;                /* in zephyr/dts/arm/infineon/cat1a/psoc6_02/psoc6_02.dtsi:579 */
			status = "disabled";                  /* in zephyr/dts/arm/infineon/cat1a/psoc6_02/psoc6_02.dtsi:580 */
		};

		/* node '/soc/counter@40390640' defined in zephyr/dts/arm/infineon/cat1a/psoc6_02/psoc6_02.dtsi:583 */
		counter1_21: counter@40390640 {
			compatible = "infineon,cat1-counter"; /* in zephyr/dts/arm/infineon/cat1a/psoc6_02/psoc6_02.dtsi:584 */
			reg = < 0x40390640 0x40 >;            /* in zephyr/dts/arm/infineon/cat1a/psoc6_02/psoc6_02.dtsi:585 */
			interrupts = < 0x98 0x6 >;            /* in zephyr/dts/arm/infineon/cat1a/psoc6_02/psoc6_02.dtsi:586 */
			resolution = < 0x10 >;                /* in zephyr/dts/arm/infineon/cat1a/psoc6_02/psoc6_02.dtsi:587 */
			status = "disabled";                  /* in zephyr/dts/arm/infineon/cat1a/psoc6_02/psoc6_02.dtsi:588 */
		};

		/* node '/soc/counter@40390680' defined in zephyr/dts/arm/infineon/cat1a/psoc6_02/psoc6_02.dtsi:591 */
		counter1_22: counter@40390680 {
			compatible = "infineon,cat1-counter"; /* in zephyr/dts/arm/infineon/cat1a/psoc6_02/psoc6_02.dtsi:592 */
			reg = < 0x40390680 0x40 >;            /* in zephyr/dts/arm/infineon/cat1a/psoc6_02/psoc6_02.dtsi:593 */
			interrupts = < 0x99 0x6 >;            /* in zephyr/dts/arm/infineon/cat1a/psoc6_02/psoc6_02.dtsi:594 */
			resolution = < 0x10 >;                /* in zephyr/dts/arm/infineon/cat1a/psoc6_02/psoc6_02.dtsi:595 */
			status = "disabled";                  /* in zephyr/dts/arm/infineon/cat1a/psoc6_02/psoc6_02.dtsi:596 */
		};

		/* node '/soc/counter@403906c0' defined in zephyr/dts/arm/infineon/cat1a/psoc6_02/psoc6_02.dtsi:599 */
		counter1_23: counter@403906c0 {
			compatible = "infineon,cat1-counter"; /* in zephyr/dts/arm/infineon/cat1a/psoc6_02/psoc6_02.dtsi:600 */
			reg = < 0x403906c0 0x40 >;            /* in zephyr/dts/arm/infineon/cat1a/psoc6_02/psoc6_02.dtsi:601 */
			interrupts = < 0x9a 0x6 >;            /* in zephyr/dts/arm/infineon/cat1a/psoc6_02/psoc6_02.dtsi:602 */
			resolution = < 0x10 >;                /* in zephyr/dts/arm/infineon/cat1a/psoc6_02/psoc6_02.dtsi:603 */
			status = "disabled";                  /* in zephyr/dts/arm/infineon/cat1a/psoc6_02/psoc6_02.dtsi:604 */
		};

		/* node '/soc/sdhc@40460000' defined in zephyr/dts/arm/infineon/cat1a/psoc6_02/psoc6_02.dtsi:607 */
		sdhc0: sdhc@40460000 {
			compatible = "infineon,cat1-sdhc-sdio";                                                        /* in zephyr/dts/arm/infineon/cat1a/psoc6_02/psoc6_02.dtsi:608 */
			reg = < 0x40460000 0x2000 >;                                                                   /* in zephyr/dts/arm/infineon/cat1a/psoc6_02/psoc6_02.dtsi:609 */
			interrupts = < 0xa4 0x6 >;                                                                     /* in zephyr/dts/arm/infineon/cat1a/psoc6_02/psoc6_02.dtsi:610 */
			status = "okay";                                                                               /* in zephyr/boards/infineon/cy8cproto_062_4343w/cy8cproto_062_4343w.dts:81 */
			pinctrl-0 = < &p2_4_sdio_cmd &p2_5_sdio_clk &p2_0_sdio_data0 &p2_1_sdio_data1 &p2_2_sdio_data2
			              &p2_3_sdio_data3 >;                                                              /* in zephyr/boards/infineon/cy8cproto_062_4343w/cy8cproto_062_4343w.dts:84 */
			pinctrl-names = "default";                                                                     /* in zephyr/boards/infineon/cy8cproto_062_4343w/cy8cproto_062_4343w.dts:86 */

			/* node '/soc/sdhc@40460000/airoc-wifi' defined in zephyr/boards/infineon/cy8cproto_062_4343w/cy8cproto_062_4343w.dts:89 */
			airoc-wifi {
				status = "okay";                               /* in zephyr/boards/infineon/cy8cproto_062_4343w/cy8cproto_062_4343w.dts:90 */
				compatible = "infineon,airoc-wifi";            /* in zephyr/boards/infineon/cy8cproto_062_4343w/cy8cproto_062_4343w.dts:91 */
				wifi-reg-on-gpios = < &gpio_prt2 0x6 0x0 >;    /* in zephyr/boards/infineon/cy8cproto_062_4343w/cy8cproto_062_4343w.dts:94 */
				wifi-host-wake-gpios = < &gpio_prt0 0x4 0x0 >; /* in zephyr/boards/infineon/cy8cproto_062_4343w/cy8cproto_062_4343w.dts:95 */
			};
		};

		/* node '/soc/dw@40280000' defined in zephyr/dts/arm/infineon/cat1a/psoc6_02/psoc6_02.dtsi:614 */
		dma0: dw@40280000 {
			#dma-cells = < 0x1 >;             /* in zephyr/dts/arm/infineon/cat1a/psoc6_02/psoc6_02.dtsi:615 */
			compatible = "infineon,cat1-dma"; /* in zephyr/dts/arm/infineon/cat1a/psoc6_02/psoc6_02.dtsi:616 */
			reg = < 0x40280000 0x8700 >;      /* in zephyr/dts/arm/infineon/cat1a/psoc6_02/psoc6_02.dtsi:617 */
			dma-channels = < 0x1d >;          /* in zephyr/dts/arm/infineon/cat1a/psoc6_02/psoc6_02.dtsi:618 */
			interrupts = < 0x38 0x6 >,
			             < 0x39 0x6 >,
			             < 0x3a 0x6 >,
			             < 0x3b 0x6 >,
			             < 0x3c 0x6 >,
			             < 0x3d 0x6 >,
			             < 0x3e 0x6 >,
			             < 0x3f 0x6 >,
			             < 0x40 0x6 >,
			             < 0x41 0x6 >,
			             < 0x42 0x6 >,
			             < 0x43 0x6 >,
			             < 0x44 0x6 >,
			             < 0x45 0x6 >,
			             < 0x46 0x6 >,
			             < 0x47 0x6 >,
			             < 0x48 0x6 >,
			             < 0x49 0x6 >,
			             < 0x4a 0x6 >,
			             < 0x4b 0x6 >,
			             < 0x4c 0x6 >,
			             < 0x4d 0x6 >,
			             < 0x4e 0x6 >,
			             < 0x4f 0x6 >,
			             < 0x50 0x6 >,
			             < 0x51 0x6 >,
			             < 0x52 0x6 >,
			             < 0x53 0x6 >,
			             < 0x54 0x6 >;        /* in zephyr/dts/arm/infineon/cat1a/psoc6_02/psoc6_02.dtsi:619 */
			status = "disabled";              /* in zephyr/dts/arm/infineon/cat1a/psoc6_02/psoc6_02.dtsi:648 */
		};

		/* node '/soc/dw@40290000' defined in zephyr/dts/arm/infineon/cat1a/psoc6_02/psoc6_02.dtsi:651 */
		dma1: dw@40290000 {
			#dma-cells = < 0x1 >;             /* in zephyr/dts/arm/infineon/cat1a/psoc6_02/psoc6_02.dtsi:652 */
			compatible = "infineon,cat1-dma"; /* in zephyr/dts/arm/infineon/cat1a/psoc6_02/psoc6_02.dtsi:653 */
			reg = < 0x40290000 0x8700 >;      /* in zephyr/dts/arm/infineon/cat1a/psoc6_02/psoc6_02.dtsi:654 */
			dma-channels = < 0x1d >;          /* in zephyr/dts/arm/infineon/cat1a/psoc6_02/psoc6_02.dtsi:655 */
			interrupts = < 0x55 0x6 >,
			             < 0x56 0x6 >,
			             < 0x57 0x6 >,
			             < 0x58 0x6 >,
			             < 0x59 0x6 >,
			             < 0x5a 0x6 >,
			             < 0x5b 0x6 >,
			             < 0x5c 0x6 >,
			             < 0x5d 0x6 >,
			             < 0x5e 0x6 >,
			             < 0x5f 0x6 >,
			             < 0x60 0x6 >,
			             < 0x61 0x6 >,
			             < 0x62 0x6 >,
			             < 0x63 0x6 >,
			             < 0x64 0x6 >,
			             < 0x65 0x6 >,
			             < 0x66 0x6 >,
			             < 0x67 0x6 >,
			             < 0x68 0x6 >,
			             < 0x69 0x6 >,
			             < 0x6a 0x6 >,
			             < 0x6b 0x6 >,
			             < 0x6c 0x6 >,
			             < 0x6d 0x6 >,
			             < 0x6e 0x6 >,
			             < 0x6f 0x6 >,
			             < 0x70 0x6 >,
			             < 0x71 0x6 >;        /* in zephyr/dts/arm/infineon/cat1a/psoc6_02/psoc6_02.dtsi:656 */
			status = "disabled";              /* in zephyr/dts/arm/infineon/cat1a/psoc6_02/psoc6_02.dtsi:685 */
		};
	};

	/* node '/cpus' defined in zephyr/dts/arm/infineon/cat1a/psoc6_02/psoc6_02.dtsi:11 */
	cpus {
		#address-cells = < 0x1 >; /* in zephyr/dts/arm/infineon/cat1a/psoc6_02/psoc6_02.dtsi:12 */
		#size-cells = < 0x0 >;    /* in zephyr/dts/arm/infineon/cat1a/psoc6_02/psoc6_02.dtsi:13 */

		/* node '/cpus/cpu@0' defined in zephyr/dts/arm/infineon/cat1a/psoc6_02/psoc6_02.dtsi:15 */
		cpu@0 {
			device_type = "cpu";           /* in zephyr/dts/arm/infineon/cat1a/psoc6_02/psoc6_02.dtsi:16 */
			compatible = "arm,cortex-m0+"; /* in zephyr/dts/arm/infineon/cat1a/psoc6_02/psoc6_02.dtsi:17 */
			reg = < 0x0 >;                 /* in zephyr/dts/arm/infineon/cat1a/psoc6_02/psoc6_02.dtsi:18 */
		};

		/* node '/cpus/cpu@1' defined in zephyr/dts/arm/infineon/cat1a/psoc6_02/psoc6_02.dtsi:21 */
		cpu@1 {
			device_type = "cpu";           /* in zephyr/dts/arm/infineon/cat1a/psoc6_02/psoc6_02.dtsi:22 */
			compatible = "arm,cortex-m4f"; /* in zephyr/dts/arm/infineon/cat1a/psoc6_02/psoc6_02.dtsi:23 */
			reg = < 0x1 >;                 /* in zephyr/dts/arm/infineon/cat1a/psoc6_02/psoc6_02.dtsi:24 */
		};
	};

	/* node '/flash-controller@40240000' defined in zephyr/dts/arm/infineon/cat1a/psoc6_02/psoc6_02.dtsi:28 */
	flash-controller@40240000 {
		compatible = "infineon,cat1-flash-controller"; /* in zephyr/dts/arm/infineon/cat1a/psoc6_02/psoc6_02.dtsi:29 */
		reg = < 0x40240000 0x10000 >;                  /* in zephyr/dts/arm/infineon/cat1a/psoc6_02/psoc6_02.dtsi:30 */
		#address-cells = < 0x1 >;                      /* in zephyr/dts/arm/infineon/cat1a/psoc6_02/psoc6_02.dtsi:31 */
		#size-cells = < 0x1 >;                         /* in zephyr/dts/arm/infineon/cat1a/psoc6_02/psoc6_02.dtsi:32 */

		/* node '/flash-controller@40240000/flash@10000000' defined in zephyr/dts/arm/infineon/cat1a/psoc6_02/psoc6_02.dtsi:34 */
		flash0: flash@10000000 {
			compatible = "soc-nv-flash";   /* in zephyr/dts/arm/infineon/cat1a/psoc6_02/psoc6_02.dtsi:35 */
			reg = < 0x10000000 0x200000 >; /* in zephyr/dts/arm/infineon/cat1a/psoc6_02/psoc6_02.dtsi:36 */
			write-block-size = < 0x200 >;  /* in zephyr/dts/arm/infineon/cat1a/psoc6_02/psoc6_02.dtsi:37 */
			erase-block-size = < 0x200 >;  /* in zephyr/dts/arm/infineon/cat1a/psoc6_02/psoc6_02.dtsi:38 */
		};

		/* node '/flash-controller@40240000/flash@14000000' defined in zephyr/dts/arm/infineon/cat1a/psoc6_02/psoc6_02.dtsi:41 */
		flash1: flash@14000000 {
			compatible = "soc-nv-flash";  /* in zephyr/dts/arm/infineon/cat1a/psoc6_02/psoc6_02.dtsi:42 */
			reg = < 0x14000000 0x8000 >;  /* in zephyr/dts/arm/infineon/cat1a/psoc6_02/psoc6_02.dtsi:43 */
			write-block-size = < 0x200 >; /* in zephyr/dts/arm/infineon/cat1a/psoc6_02/psoc6_02.dtsi:44 */
			erase-block-size = < 0x200 >; /* in zephyr/dts/arm/infineon/cat1a/psoc6_02/psoc6_02.dtsi:45 */
		};
	};

	/* node '/memory@8000000' defined in zephyr/dts/arm/infineon/cat1a/psoc6_02/psoc6_02.dtsi:49 */
	sram0: memory@8000000 {
		compatible = "mmio-sram";     /* in zephyr/dts/arm/infineon/cat1a/psoc6_02/psoc6_02.dtsi:50 */
		reg = < 0x8000000 0x100000 >; /* in zephyr/dts/arm/infineon/cat1a/psoc6_02/psoc6_02.dtsi:51 */
	};

	/* node '/clocks' defined in zephyr/dts/arm/infineon/cat1a/system_clocks.dtsi:9 */
	clocks {

		/* node '/clocks/clk_imo' defined in zephyr/dts/arm/infineon/cat1a/system_clocks.dtsi:11 */
		clk_imo: clk_imo {
			#clock-cells = < 0x0 >;         /* in zephyr/dts/arm/infineon/cat1a/system_clocks.dtsi:12 */
			compatible = "fixed-clock";     /* in zephyr/dts/arm/infineon/cat1a/system_clocks.dtsi:13 */
			clock-frequency = < 0x7a1200 >; /* in zephyr/dts/arm/infineon/cat1a/system_clocks.dtsi:14 */
			status = "okay";                /* in zephyr/dts/arm/infineon/cat1a/system_clocks.dtsi:15 */
			phandle = < 0x13 >;             /* in zephyr/dts/arm/infineon/cat1a/system_clocks.dtsi:22 */
		};

		/* node '/clocks/path_mux0' defined in zephyr/dts/arm/infineon/cat1a/system_clocks.dtsi:19 */
		path_mux0: path_mux0 {
			#clock-cells = < 0x0 >;            /* in zephyr/dts/arm/infineon/cat1a/system_clocks.dtsi:20 */
			compatible = "fixed-factor-clock"; /* in zephyr/dts/arm/infineon/cat1a/system_clocks.dtsi:21 */
			clocks = < &clk_imo >;             /* in zephyr/dts/arm/infineon/cat1a/system_clocks.dtsi:22 */
			status = "okay";                   /* in zephyr/dts/arm/infineon/cat1a/system_clocks.dtsi:23 */
		};

		/* node '/clocks/path_mux1' defined in zephyr/dts/arm/infineon/cat1a/system_clocks.dtsi:27 */
		path_mux1: path_mux1 {
			#clock-cells = < 0x0 >;            /* in zephyr/dts/arm/infineon/cat1a/system_clocks.dtsi:28 */
			compatible = "fixed-factor-clock"; /* in zephyr/dts/arm/infineon/cat1a/system_clocks.dtsi:29 */
			clocks = < &clk_imo >;             /* in zephyr/dts/arm/infineon/cat1a/system_clocks.dtsi:30 */
			status = "okay";                   /* in zephyr/dts/arm/infineon/cat1a/system_clocks.dtsi:31 */
			phandle = < 0x15 >;                /* in zephyr/dts/arm/infineon/cat1a/system_clocks.dtsi:88 */
		};

		/* node '/clocks/path_mux2' defined in zephyr/dts/arm/infineon/cat1a/system_clocks.dtsi:35 */
		path_mux2: path_mux2 {
			#clock-cells = < 0x0 >;            /* in zephyr/dts/arm/infineon/cat1a/system_clocks.dtsi:36 */
			compatible = "fixed-factor-clock"; /* in zephyr/dts/arm/infineon/cat1a/system_clocks.dtsi:37 */
			clocks = < &clk_imo >;             /* in zephyr/dts/arm/infineon/cat1a/system_clocks.dtsi:38 */
			status = "disabled";               /* in zephyr/dts/arm/infineon/cat1a/system_clocks.dtsi:39 */
			phandle = < 0x16 >;                /* in zephyr/dts/arm/infineon/cat1a/system_clocks.dtsi:97 */
		};

		/* node '/clocks/path_mux3' defined in zephyr/dts/arm/infineon/cat1a/system_clocks.dtsi:43 */
		path_mux3: path_mux3 {
			#clock-cells = < 0x0 >;            /* in zephyr/dts/arm/infineon/cat1a/system_clocks.dtsi:44 */
			compatible = "fixed-factor-clock"; /* in zephyr/dts/arm/infineon/cat1a/system_clocks.dtsi:45 */
			clocks = < &clk_imo >;             /* in zephyr/dts/arm/infineon/cat1a/system_clocks.dtsi:46 */
			status = "disabled";               /* in zephyr/dts/arm/infineon/cat1a/system_clocks.dtsi:47 */
			phandle = < 0x17 >;                /* in zephyr/dts/arm/infineon/cat1a/system_clocks.dtsi:106 */
		};

		/* node '/clocks/path_mux4' defined in zephyr/dts/arm/infineon/cat1a/system_clocks.dtsi:51 */
		path_mux4: path_mux4 {
			#clock-cells = < 0x0 >;            /* in zephyr/dts/arm/infineon/cat1a/system_clocks.dtsi:52 */
			compatible = "fixed-factor-clock"; /* in zephyr/dts/arm/infineon/cat1a/system_clocks.dtsi:53 */
			clocks = < &clk_imo >;             /* in zephyr/dts/arm/infineon/cat1a/system_clocks.dtsi:54 */
			status = "disabled";               /* in zephyr/dts/arm/infineon/cat1a/system_clocks.dtsi:55 */
			phandle = < 0x18 >;                /* in zephyr/dts/arm/infineon/cat1a/system_clocks.dtsi:115 */
		};

		/* node '/clocks/fll0' defined in zephyr/dts/arm/infineon/cat1a/system_clocks.dtsi:59 */
		fll0: fll0 {
			#clock-cells = < 0x0 >;          /* in zephyr/dts/arm/infineon/cat1a/system_clocks.dtsi:60 */
			compatible = "fixed-clock";      /* in zephyr/dts/arm/infineon/cat1a/system_clocks.dtsi:61 */
			status = "okay";                 /* in zephyr/boards/infineon/cy8cproto_062_4343w/cy8cproto_062_4343w.dts:101 */
			clock-frequency = < 0x5f5e100 >; /* in zephyr/boards/infineon/cy8cproto_062_4343w/cy8cproto_062_4343w.dts:102 */
			phandle = < 0x14 >;              /* in zephyr/boards/infineon/cy8cproto_062_4343w/cy8cproto_062_4343w.dts:107 */
		};

		/* node '/clocks/pll0' defined in zephyr/dts/arm/infineon/cat1a/system_clocks.dtsi:67 */
		pll0: pll0 {
			#clock-cells = < 0x0 >;     /* in zephyr/dts/arm/infineon/cat1a/system_clocks.dtsi:68 */
			compatible = "fixed-clock"; /* in zephyr/dts/arm/infineon/cat1a/system_clocks.dtsi:69 */
			status = "disabled";        /* in zephyr/dts/arm/infineon/cat1a/system_clocks.dtsi:71 */
		};

		/* node '/clocks/clk_hf0' defined in zephyr/dts/arm/infineon/cat1a/system_clocks.dtsi:75 */
		clk_hf0: clk_hf0 {
			#clock-cells = < 0x0 >;            /* in zephyr/dts/arm/infineon/cat1a/system_clocks.dtsi:76 */
			compatible = "fixed-factor-clock"; /* in zephyr/dts/arm/infineon/cat1a/system_clocks.dtsi:77 */
			status = "okay";                   /* in zephyr/dts/arm/infineon/cat1a/system_clocks.dtsi:80 */
			clock-div = < 0x1 >;               /* in zephyr/boards/infineon/cy8cproto_062_4343w/cy8cproto_062_4343w.dts:106 */
			clocks = < &fll0 >;                /* in zephyr/boards/infineon/cy8cproto_062_4343w/cy8cproto_062_4343w.dts:107 */
		};

		/* node '/clocks/clk_hf1' defined in zephyr/dts/arm/infineon/cat1a/system_clocks.dtsi:84 */
		clk_hf1: clk_hf1 {
			#clock-cells = < 0x0 >;            /* in zephyr/dts/arm/infineon/cat1a/system_clocks.dtsi:85 */
			compatible = "fixed-factor-clock"; /* in zephyr/dts/arm/infineon/cat1a/system_clocks.dtsi:86 */
			clock-div = < 0x1 >;               /* in zephyr/dts/arm/infineon/cat1a/system_clocks.dtsi:87 */
			clocks = < &path_mux1 >;           /* in zephyr/dts/arm/infineon/cat1a/system_clocks.dtsi:88 */
			status = "disabled";               /* in zephyr/dts/arm/infineon/cat1a/system_clocks.dtsi:89 */
		};

		/* node '/clocks/clk_hf2' defined in zephyr/dts/arm/infineon/cat1a/system_clocks.dtsi:93 */
		clk_hf2: clk_hf2 {
			#clock-cells = < 0x0 >;            /* in zephyr/dts/arm/infineon/cat1a/system_clocks.dtsi:94 */
			compatible = "fixed-factor-clock"; /* in zephyr/dts/arm/infineon/cat1a/system_clocks.dtsi:95 */
			clock-div = < 0x1 >;               /* in zephyr/dts/arm/infineon/cat1a/system_clocks.dtsi:96 */
			clocks = < &path_mux2 >;           /* in zephyr/dts/arm/infineon/cat1a/system_clocks.dtsi:97 */
			status = "disabled";               /* in zephyr/dts/arm/infineon/cat1a/system_clocks.dtsi:98 */
		};

		/* node '/clocks/clk_hf3' defined in zephyr/dts/arm/infineon/cat1a/system_clocks.dtsi:102 */
		clk_hf3: clk_hf3 {
			#clock-cells = < 0x0 >;            /* in zephyr/dts/arm/infineon/cat1a/system_clocks.dtsi:103 */
			compatible = "fixed-factor-clock"; /* in zephyr/dts/arm/infineon/cat1a/system_clocks.dtsi:104 */
			clock-div = < 0x1 >;               /* in zephyr/dts/arm/infineon/cat1a/system_clocks.dtsi:105 */
			clocks = < &path_mux3 >;           /* in zephyr/dts/arm/infineon/cat1a/system_clocks.dtsi:106 */
			status = "disabled";               /* in zephyr/dts/arm/infineon/cat1a/system_clocks.dtsi:107 */
		};

		/* node '/clocks/clk_hf4' defined in zephyr/dts/arm/infineon/cat1a/system_clocks.dtsi:111 */
		clk_hf4: clk_hf4 {
			#clock-cells = < 0x0 >;            /* in zephyr/dts/arm/infineon/cat1a/system_clocks.dtsi:112 */
			compatible = "fixed-factor-clock"; /* in zephyr/dts/arm/infineon/cat1a/system_clocks.dtsi:113 */
			clock-div = < 0x1 >;               /* in zephyr/dts/arm/infineon/cat1a/system_clocks.dtsi:114 */
			clocks = < &path_mux4 >;           /* in zephyr/dts/arm/infineon/cat1a/system_clocks.dtsi:115 */
			status = "disabled";               /* in zephyr/dts/arm/infineon/cat1a/system_clocks.dtsi:116 */
		};

		/* node '/clocks/clk_fast' defined in zephyr/dts/arm/infineon/cat1a/system_clocks.dtsi:120 */
		clk_fast: clk_fast {
			#clock-cells = < 0x0 >;            /* in zephyr/dts/arm/infineon/cat1a/system_clocks.dtsi:121 */
			compatible = "fixed-factor-clock"; /* in zephyr/dts/arm/infineon/cat1a/system_clocks.dtsi:122 */
			status = "okay";                   /* in zephyr/dts/arm/infineon/cat1a/system_clocks.dtsi:124 */
			clock-div = < 0x1 >;               /* in zephyr/boards/infineon/cy8cproto_062_4343w/cy8cproto_062_4343w.dts:114 */
		};

		/* node '/clocks/clk_slow' defined in zephyr/dts/arm/infineon/cat1a/system_clocks.dtsi:128 */
		clk_slow: clk_slow {
			#clock-cells = < 0x0 >;            /* in zephyr/dts/arm/infineon/cat1a/system_clocks.dtsi:129 */
			compatible = "fixed-factor-clock"; /* in zephyr/dts/arm/infineon/cat1a/system_clocks.dtsi:130 */
			status = "okay";                   /* in zephyr/dts/arm/infineon/cat1a/system_clocks.dtsi:132 */
			clock-div = < 0x2 >;               /* in zephyr/boards/infineon/cy8cproto_062_4343w/cy8cproto_062_4343w.dts:121 */
		};

		/* node '/clocks/clk_peri' defined in zephyr/dts/arm/infineon/cat1a/system_clocks.dtsi:136 */
		clk_peri: clk_peri {
			#clock-cells = < 0x0 >;            /* in zephyr/dts/arm/infineon/cat1a/system_clocks.dtsi:137 */
			compatible = "fixed-factor-clock"; /* in zephyr/dts/arm/infineon/cat1a/system_clocks.dtsi:138 */
			status = "okay";                   /* in zephyr/dts/arm/infineon/cat1a/system_clocks.dtsi:140 */
			clock-div = < 0x1 >;               /* in zephyr/boards/infineon/cy8cproto_062_4343w/cy8cproto_062_4343w.dts:128 */
		};
	};

	/* node '/leds' defined in zephyr/boards/infineon/cy8cproto_062_4343w/cy8cproto_062_4343w-common.dtsi:14 */
	leds {
		compatible = "gpio-leds"; /* in zephyr/boards/infineon/cy8cproto_062_4343w/cy8cproto_062_4343w-common.dtsi:15 */

		/* node '/leds/led_0' defined in zephyr/boards/infineon/cy8cproto_062_4343w/cy8cproto_062_4343w-common.dtsi:17 */
		user_led: led_0 {
			label = "LED_0";                 /* in zephyr/boards/infineon/cy8cproto_062_4343w/cy8cproto_062_4343w-common.dtsi:18 */
			gpios = < &gpio_prt13 0x7 0x1 >; /* in zephyr/boards/infineon/cy8cproto_062_4343w/cy8cproto_062_4343w-common.dtsi:19 */
		};
	};

	/* node '/gpio_keys' defined in zephyr/boards/infineon/cy8cproto_062_4343w/cy8cproto_062_4343w-common.dtsi:23 */
	gpio_keys {
		compatible = "gpio-keys"; /* in zephyr/boards/infineon/cy8cproto_062_4343w/cy8cproto_062_4343w-common.dtsi:24 */

		/* node '/gpio_keys/button_0' defined in zephyr/boards/infineon/cy8cproto_062_4343w/cy8cproto_062_4343w-common.dtsi:26 */
		user_bt: button_0 {
			label = "SW_0";                  /* in zephyr/boards/infineon/cy8cproto_062_4343w/cy8cproto_062_4343w-common.dtsi:27 */
			gpios = < &gpio_prt0 0x4 0x11 >; /* in zephyr/boards/infineon/cy8cproto_062_4343w/cy8cproto_062_4343w-common.dtsi:28 */
			zephyr,code = < 0xb >;           /* in zephyr/boards/infineon/cy8cproto_062_4343w/cy8cproto_062_4343w-common.dtsi:29 */
		};
	};
};
